AUTOSAR XML (schema 00044)
package /E40_Platform_System_SystemPackage/Components
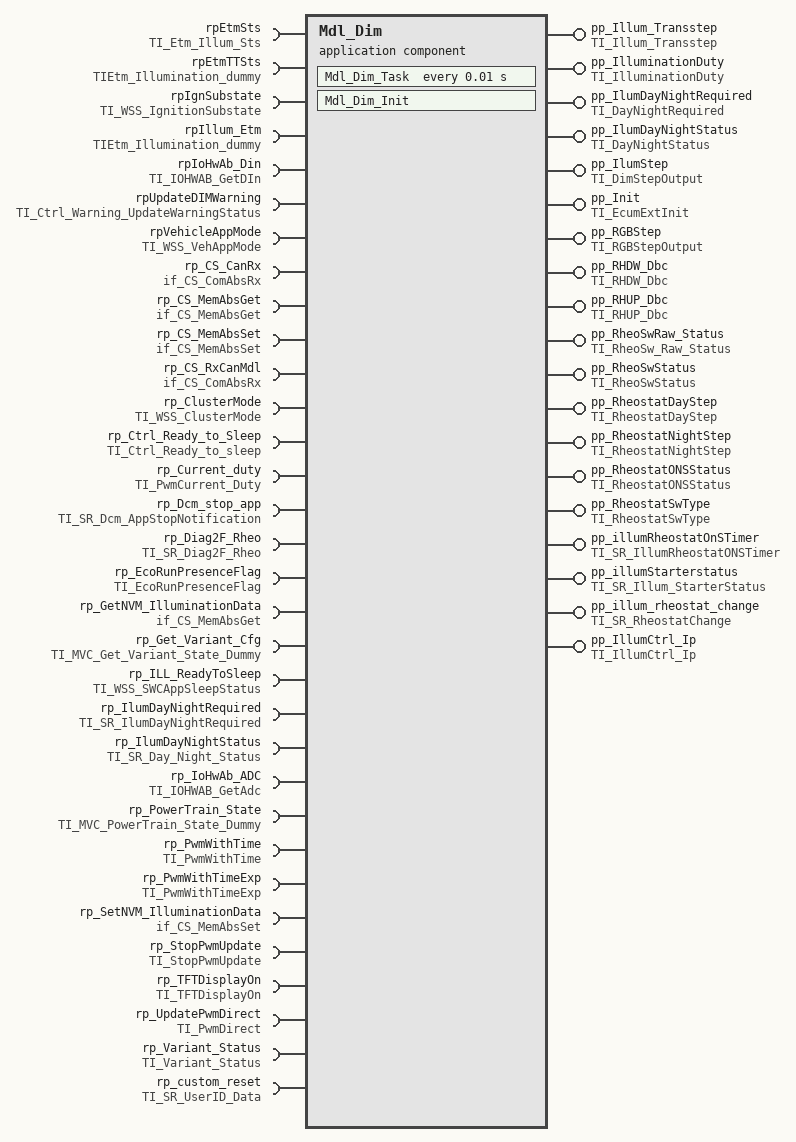
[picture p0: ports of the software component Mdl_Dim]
  application sw component type Mdl_Dim
    18 x provide port:
      pp_Illum_Transstep: nonqueued-sender-com-spec{data-element=Trans_Stepvlaue, init-value=constant-reference=Mdl_DimTrans_StepvlaueValue0}, provided-interface=TI_Illum_Transstep
      pp_IlluminationDuty: nonqueued-sender-com-spec{data-element=DutyValue, init-value=constant-reference=Mdl_DimDutyValueValue0}, provided-interface=TI_IlluminationDuty
      pp_IlumDayNightRequired: nonqueued-sender-com-spec{data-element=ilumDNRequired, init-value=constant-reference=Mdl_DimilumDNRequiredValue0}, provided-interface=TI_DayNightRequired
      pp_IlumDayNightStatus: nonqueued-sender-com-spec{data-element=illumDNStatus, init-value=constant-reference=Mdl_DimillumDNStatusValue0}, provided-interface=TI_DayNightStatus
      pp_IlumStep: nonqueued-sender-com-spec{data-element=IllumStepValue, init-value=constant-reference=Mdl_DimIllumStepValueValue0}, provided-interface=TI_DimStepOutput
      pp_Init: server-com-spec{operation=Init, queue-length=1}, provided-interface=TI_EcumExtInit
      pp_RGBStep: nonqueued-sender-com-spec{data-element=RGBStepValue, init-value=constant-reference=Mdl_DimRGBStepValueValue0}, provided-interface=TI_RGBStepOutput
      pp_RHDW_Dbc: nonqueued-sender-com-spec{data-element=RHDW_Dbc, init-value=constant-reference=Mdl_DimRHDW_DbcValue0}, provided-interface=TI_RHDW_Dbc
      pp_RHUP_Dbc: nonqueued-sender-com-spec{data-element=RHUP_Dbc, init-value=constant-reference=Mdl_DimRHUP_DbcValue0}, provided-interface=TI_RHUP_Dbc
      pp_RheoSwRaw_Status: nonqueued-sender-com-spec{data-element=RawdataStatus, init-value=constant-reference=Mdl_DimRawdataStatusValue0}, provided-interface=TI_RheoSw_Raw_Status
      pp_RheoSwStatus: nonqueued-sender-com-spec{data-element=SwitchStatus, init-value=constant-reference=Mdl_DimSwitchStatusValue0}, provided-interface=TI_RheoSwStatus
      pp_RheostatDayStep: nonqueued-sender-com-spec{data-element=RheostatDayStep, init-value=constant-reference=Mdl_DimRheostatDayStepValue0}, provided-interface=TI_RheostatDayStep
      pp_RheostatNightStep: nonqueued-sender-com-spec{data-element=RheostatNightStep, init-value=constant-reference=Mdl_DimRheostatNightStepValue0}, provided-interface=TI_RheostatNightStep
      pp_RheostatONSStatus: nonqueued-sender-com-spec{data-element=RheostatONSStatus, init-value=constant-reference=Mdl_DimRheostatONSStatusValue0}, provided-interface=TI_RheostatONSStatus
      pp_RheostatSwType: nonqueued-sender-com-spec{data-element=RheostatSwType, init-value=constant-reference=Mdl_DimRheostatSwTypeValue0}, provided-interface=TI_RheostatSwType
      pp_illumRheostatOnSTimer: nonqueued-sender-com-spec{data-element=Rheostat_OnSTime, init-value=constant-reference=Mdl_DimRheostat_OnSTimeValue0}, provided-interface=TI_SR_IllumRheostatONSTimer
      pp_illumStarterstatus: nonqueued-sender-com-spec{data-element=StarterStatus_Out, init-value=constant-reference=Mdl_DimStarterStatus_OutValue0}, provided-interface=TI_SR_Illum_StarterStatus
      pp_illum_rheostat_change: nonqueued-sender-com-spec{data-element=RheoUpdateVal, init-value=constant-reference=Mdl_DimRheoUpdateValValue0}, provided-interface=TI_SR_RheostatChange
    32 x require port:
      rpEtmSts: nonqueued-receiver-com-spec{data-element=Illum_Status, init-value=constant-reference=Mdl_DimIllum_StatusValue0}, required-interface=TI_Etm_Illum_Sts
      rpEtmTTSts: nonqueued-receiver-com-spec{data-element=IllumStatus, init-value=constant-reference=Mdl_DimIllumStatusValue0}, required-interface=TIEtm_Illumination_dummy
      rpIgnSubstate: nonqueued-receiver-com-spec{data-element=IgnitionSubstate, init-value=constant-reference=Mdl_DimIgnitionSubstateValue0}, required-interface=TI_WSS_IgnitionSubstate
      rpIllum_Etm: nonqueued-receiver-com-spec{data-element=IllumStatus, init-value=constant-reference=Mdl_DimIllumStatusValue0}, required-interface=TIEtm_Illumination_dummy
      rpIoHwAb_Din: required-com-specs=[GetAsyncRawInput, GetInputGroup, GetProcessedInput, GetSyncRawInput], required-interface=TI_IOHWAB_GetDIn
      rpUpdateDIMWarning: client-com-spec=UpdateWarningStatus, required-interface=TI_Ctrl_Warning_UpdateWarningStatus
      rpVehicleAppMode: nonqueued-receiver-com-spec{data-element=WSSCurrentVehicleState, init-value=constant-reference=Mdl_DimWSSCurrentVehicleStateValue0}, required-interface=TI_WSS_VehAppMode
      rp_CS_CanRx: required-interface=if_CS_ComAbsRx
        required-com-specs:
          RxCan_GetSignalValue
          RxCan_GetSignalValueU8Arr
          RxCan_SetSignalInitValue
          RxCan_SetSignalInitValueU8Arr
          RxCan_SignalClearJustRcvdStatus
          RxCan_SignalGetJustRcvdStatus
          RxCan_SignalInvalidProcessingControl
          RxCan_SignalMissingProcessingControl
          RxCan_SignalNRProcessingControl
      rp_CS_MemAbsGet: required-interface=if_CS_MemAbsGet
        required-com-specs:
          Get_BsConst_Audio_Element
          Get_BsConst_Communication_Element
          Get_BsConst_EngOffTimer_Element
          Get_BsConst_FuelGauge_Element
          Get_BsConst_OilGauge_Element
          Get_BsConst_PowerGauge_Element
          Get_BsConst_Power_Element
          Get_BsConst_RealTimeClock_Element
          Get_BsConst_ServiceReminder_Element
          Get_BsConst_SpeedoGauge_Element
          Get_BsConst_TachoGauge_Element
          Get_BsConst_TempGauge_Element
          Get_BsConst_TripComputer_Element
          Get_BsConst_Warning_Element
          Get_BsCys_Certicificate_Element
          Get_BsDiag_Dtc_Element
          Get_BsDiag_ErrorRecord_Element
          Get_BsReten_Audio_Element
          Get_BsReten_Communication_Element
          Get_BsReten_Display_Element
          Get_BsReten_Gauges_Element
          Get_BsReten_Illumination_Element
          Get_BsReten_Odometer_Element
          Get_BsReten_Personalization_Element
          Get_BsReten_Power_Element
          Get_BsReten_RealTimeClock_Element
          Get_BsReten_Tripcomputer_Element
          Get_BsReten_Warning_Element
          Get_BsRt_CusDlt_Element
          Get_BsRt_FuelGauge_Element
          Get_BsRt_Illumination_Element
          Get_BsRt_Odometer_Element
          Get_BsRt_OilGauge_Element
          Get_BsRt_Personalization_Element
          Get_BsRt_PowerGauge_Element
          Get_BsRt_RealTimeClock_Element
          Get_BsRt_SpeedoGauge_Element
          Get_BsRt_TachoGauge_Element
          Get_BsRt_TempGauge_Element
          Get_BsRt_TripComputer_Element
          Get_BsRt_Warning_Element
          Get_BsShare_EcuPartNumber_Element
          Get_BsShare_SwUpdFotaFinPrint_Element
          Get_BsShare_SwUpdFotaMode_Element
          Get_BsShare_SwUpdFotaStatus_Element
          Get_BsShare_SwUpdFotadecrypt_Element
          Get_BsShare_SwUpdReflash_Element
          Get_BsShare_VehicleConfig_Element
          Get_BsShare_VisMeet_Element
          Get_RefCys_Certicificate1_Element
          Get_RefCys_Certicificate_Element
          Get_BsShare_VisMeet_EOLEntry_Element
          Get_BsShare_AssemblyManufacturingDate
          Get_BsShare_AssemblyPlantNumber
          Get_BsShare_HWModification
          Get_BsShare_PCBSerialNumber
          Get_BsShare_ProductSerialNumber
          Get_BsShare_SMTManufacturingDate
          Get_BsShare_SMTPlantNumber
          Get_BsShare_VisteonPCBPartNumber
          Get_BsShare_VisteonPartNumber
          Get_BsConst_Temperature_Sensor_Conv_SafeCopy2
          Get_BsConst_Temperature_Sensor_Conv_SafeCopy1
          Get_BsConst_Temperature_Sensor_Conv
          Get_BsConst_Temp_Threshold_Hysteresis_Derating_SafeCopy2
          Get_BsConst_Temp_Threshold_Hysteresis_Derating_SafeCopy1
          Get_BsConst_Temp_Threshold_Hysteresis_Derating
          Get_BsConst_PWM_boost_bypass_duty_SafeCopy2
          Get_BsConst_PWM_boost_bypass_duty_SafeCopy1
          Get_BsConst_PWM_boost_bypass_duty
          Get_BsConst_PCB_Temperature_Sensor_Conv_SafeCopy2
          Get_BsConst_PCB_Temperature_Sensor_Conv_SafeCopy1
          Get_BsConst_PCB_Temperature_Sensor_Conv
          Get_BsConst_Lookup_Curve_HotSpot_Coef_Y_SafeCopy2
          Get_BsConst_Lookup_Curve_HotSpot_Coef_Y_SafeCopy1
          Get_BsConst_Lookup_Curve_HotSpot_Coef_Y
          Get_BsConst_Lookup_Curve_HotSpot_Coef_X_SafeCopy2
          Get_BsConst_Lookup_Curve_HotSpot_Coef_X_SafeCopy1
          Get_BsConst_Lookup_Curve_HotSpot_Coef_X
          Get_BsConst_Display_Illum_Max_Level_SafeCopy2
          Get_BsConst_Display_Illum_Max_Level_SafeCopy1
          Get_BsConst_Display_Illum_Max_Level
          Get_BsConst_Derating_Backlight_Disable_SafeCopy2
          Get_BsConst_Derating_Backlight_Disable_SafeCopy1
          Get_BsConst_Derating_Backlight_Disable
          Get_BsConst_Compensation_Line_Slope_m_SafeCopy2
          Get_BsConst_Compensation_Line_Slope_m_SafeCopy1
          Get_BsConst_Compensation_Line_Slope_m
          Get_BsConst_Compensation_Line_Shift_b_SafeCopy2
          Get_BsConst_Compensation_Line_Shift_b_SafeCopy1
          Get_BsConst_Compensation_Line_Shift_b
          Get_BsConst_BsConst_Illumination_ReservedByte_SafeCopy2
          Get_BsConst_BsConst_Illumination_ReservedByte_SafeCopy1
          Get_BsConst_BsConst_Illumination_ReservedByte
      rp_CS_MemAbsSet: required-interface=if_CS_MemAbsSet
        required-com-specs:
          Set_BsConst_Audio_Element
          Set_BsConst_Communication_Element
          Set_BsConst_EngOffTimer_Element
          Set_BsConst_FuelGauge_Element
          Set_BsConst_OilGauge_Element
          Set_BsConst_PowerGauge_Element
          Set_BsConst_Power_Element
          Set_BsConst_RealTimeClock_Element
          Set_BsConst_ServiceReminder_Element
          Set_BsConst_SpeedoGauge_Element
          Set_BsConst_TachoGauge_Element
          Set_BsConst_TempGauge_Element
          Set_BsConst_TripComputer_Element
          Set_BsConst_Warning_Element
          Set_BsCys_Certicificate_Element
          Set_BsDiag_Dtc_Element
          Set_BsDiag_ErrorRecord_Element
          Set_BsReten_Audio_Element
          Set_BsReten_Communication_Element
          Set_BsReten_Display_Element
          Set_BsReten_Gauges_Element
          Set_BsReten_Illumination_Element
          Set_BsReten_Odometer_Element
          Set_BsReten_Personalization_Element
          Set_BsReten_Power_Element
          Set_BsReten_RealTimeClock_Element
          Set_BsReten_Tripcomputer_Element
          Set_BsReten_Warning_Element
          Set_BsRt_CusDlt_Element
          Set_BsRt_FuelGauge_Element
          Set_BsRt_Illumination_Element
          Set_BsRt_Odometer_Element
          Set_BsRt_OilGauge_Element
          Set_BsRt_Personalization_Element
          Set_BsRt_PowerGauge_Element
          Set_BsRt_RealTimeClock_Element
          Set_BsRt_SpeedoGauge_Element
          Set_BsRt_TachoGauge_Element
          Set_BsRt_TempGauge_Element
          Set_BsRt_TripComputer_Element
          Set_BsRt_Warning_Element
          Set_BsShare_EcuPartNumber_Element
          Set_BsShare_SwUpdFotaFinPrint_Element
          Set_BsShare_SwUpdFotaMode_Element
          Set_BsShare_SwUpdFotaStatus_Element
          Set_BsShare_SwUpdFotadecrypt_Element
          Set_BsShare_SwUpdReflash_Element
          Set_BsShare_VehicleConfig_Element
          Set_BsShare_VisMeet_Element
          Set_RefCys_Certicificate1_Element
          Set_RefCys_Certicificate_Element
          Set_BsShare_VisMeet_EOLEntry_Element
          Set_BsShare_AssemblyManufacturingDate
          Set_BsShare_AssemblyPlantNumber
          Set_BsShare_HWModification
          Set_BsShare_PCBSerialNumber
          Set_BsShare_ProductSerialNumber
          Set_BsShare_SMTManufacturingDate
          Set_BsShare_SMTPlantNumber
          Set_BsShare_VisteonPCBPartNumber
          Set_BsShare_VisteonPartNumber
          Set_BsConst_Temperature_Sensor_Conv_SafeCopy2
          Set_BsConst_Temperature_Sensor_Conv_SafeCopy1
          Set_BsConst_Temperature_Sensor_Conv
          Set_BsConst_Temp_Threshold_Hysteresis_Derating_SafeCopy2
          Set_BsConst_Temp_Threshold_Hysteresis_Derating_SafeCopy1
          Set_BsConst_Temp_Threshold_Hysteresis_Derating
          Set_BsConst_PWM_boost_bypass_duty_SafeCopy2
          Set_BsConst_PWM_boost_bypass_duty_SafeCopy1
          Set_BsConst_PWM_boost_bypass_duty
          Set_BsConst_PCB_Temperature_Sensor_Conv_SafeCopy2
          Set_BsConst_PCB_Temperature_Sensor_Conv_SafeCopy1
          Set_BsConst_PCB_Temperature_Sensor_Conv
          Set_BsConst_Lookup_Curve_HotSpot_Coef_Y_SafeCopy2
          Set_BsConst_Lookup_Curve_HotSpot_Coef_Y_SafeCopy1
          Set_BsConst_Lookup_Curve_HotSpot_Coef_Y
          Set_BsConst_Lookup_Curve_HotSpot_Coef_X_SafeCopy2
          Set_BsConst_Lookup_Curve_HotSpot_Coef_X_SafeCopy1
          Set_BsConst_Lookup_Curve_HotSpot_Coef_X
          Set_BsConst_Display_Illum_Max_Level_SafeCopy2
          Set_BsConst_Display_Illum_Max_Level_SafeCopy1
          Set_BsConst_Display_Illum_Max_Level
          Set_BsConst_Derating_Backlight_Disable_SafeCopy2
          Set_BsConst_Derating_Backlight_Disable_SafeCopy1
          Set_BsConst_Derating_Backlight_Disable
          Set_BsConst_Compensation_Line_Slope_m_SafeCopy2
          Set_BsConst_Compensation_Line_Slope_m_SafeCopy1
          Set_BsConst_Compensation_Line_Slope_m
          Set_BsConst_Compensation_Line_Shift_b_SafeCopy2
          Set_BsConst_Compensation_Line_Shift_b_SafeCopy1
          Set_BsConst_Compensation_Line_Shift_b
          Set_BsConst_BsConst_Illumination_ReservedByte_SafeCopy2
          Set_BsConst_BsConst_Illumination_ReservedByte_SafeCopy1
          Set_BsConst_BsConst_Illumination_ReservedByte
      rp_CS_RxCanMdl: required-interface=if_CS_ComAbsRx
        required-com-specs:
          RxCan_GetSignalValue
          RxCan_GetSignalValueU8Arr
          RxCan_SetSignalInitValue
          RxCan_SetSignalInitValueU8Arr
          RxCan_SignalClearJustRcvdStatus
          RxCan_SignalGetJustRcvdStatus
          RxCan_SignalInvalidProcessingControl
          RxCan_SignalMissingProcessingControl
          RxCan_SignalNRProcessingControl
      rp_ClusterMode: nonqueued-receiver-com-spec{data-element=WSSCurrentClusterMode, init-value=constant-reference=Mdl_DimWSSCurrentClusterModeValue0}, required-interface=TI_WSS_ClusterMode
      rp_Ctrl_Ready_to_Sleep: nonqueued-receiver-com-spec{data-element=Ready_to_Sleep, init-value=constant-reference=Mdl_DimReady_to_SleepValue0}, required-interface=TI_Ctrl_Ready_to_sleep
      rp_Current_duty: client-com-spec=GetPwmCurrentDuty, required-interface=TI_PwmCurrent_Duty
      rp_Dcm_stop_app: nonqueued-receiver-com-spec{data-element=AppId, init-value=constant-reference=Mdl_DimAppIdValue0}, required-interface=TI_SR_Dcm_AppStopNotification
      rp_Diag2F_Rheo: nonqueued-receiver-com-spec{data-element=Diag_RheoStat, init-value=constant-reference=Mdl_DimDiag_RheoStatValue0}, required-interface=TI_SR_Diag2F_Rheo
      rp_EcoRunPresenceFlag: nonqueued-receiver-com-spec{data-element=EcoRunPresenceFlag, init-value=constant-reference=Mdl_DimEcoRunPresenceFlagValue0}, required-interface=TI_EcoRunPresenceFlag
      rp_GetNVM_IlluminationData: required-interface=if_CS_MemAbsGet
        required-com-specs:
          Get_BsConst_Audio_Element
          Get_BsConst_Communication_Element
          Get_BsConst_EngOffTimer_Element
          Get_BsConst_FuelGauge_Element
          Get_BsConst_OilGauge_Element
          Get_BsConst_PowerGauge_Element
          Get_BsConst_Power_Element
          Get_BsConst_RealTimeClock_Element
          Get_BsConst_ServiceReminder_Element
          Get_BsConst_SpeedoGauge_Element
          Get_BsConst_TachoGauge_Element
          Get_BsConst_TempGauge_Element
          Get_BsConst_TripComputer_Element
          Get_BsConst_Warning_Element
          Get_BsCys_Certicificate_Element
          Get_BsDiag_Dtc_Element
          Get_BsDiag_ErrorRecord_Element
          Get_BsReten_Audio_Element
          Get_BsReten_Communication_Element
          Get_BsReten_Display_Element
          Get_BsReten_Gauges_Element
          Get_BsReten_Illumination_Element
          Get_BsReten_Odometer_Element
          Get_BsReten_Personalization_Element
          Get_BsReten_Power_Element
          Get_BsReten_RealTimeClock_Element
          Get_BsReten_Tripcomputer_Element
          Get_BsReten_Warning_Element
          Get_BsRt_CusDlt_Element
          Get_BsRt_FuelGauge_Element
          Get_BsRt_Illumination_Element
          Get_BsRt_Odometer_Element
          Get_BsRt_OilGauge_Element
          Get_BsRt_Personalization_Element
          Get_BsRt_PowerGauge_Element
          Get_BsRt_RealTimeClock_Element
          Get_BsRt_SpeedoGauge_Element
          Get_BsRt_TachoGauge_Element
          Get_BsRt_TempGauge_Element
          Get_BsRt_TripComputer_Element
          Get_BsRt_Warning_Element
          Get_BsShare_EcuPartNumber_Element
          Get_BsShare_SwUpdFotaFinPrint_Element
          Get_BsShare_SwUpdFotaMode_Element
          Get_BsShare_SwUpdFotaStatus_Element
          Get_BsShare_SwUpdFotadecrypt_Element
          Get_BsShare_SwUpdReflash_Element
          Get_BsShare_VehicleConfig_Element
          Get_BsShare_VisMeet_Element
          Get_RefCys_Certicificate1_Element
          Get_RefCys_Certicificate_Element
          Get_BsShare_VisMeet_EOLEntry_Element
          Get_BsShare_AssemblyManufacturingDate
          Get_BsShare_AssemblyPlantNumber
          Get_BsShare_HWModification
          Get_BsShare_PCBSerialNumber
          Get_BsShare_ProductSerialNumber
          Get_BsShare_SMTManufacturingDate
          Get_BsShare_SMTPlantNumber
          Get_BsShare_VisteonPCBPartNumber
          Get_BsShare_VisteonPartNumber
          Get_BsConst_Temperature_Sensor_Conv_SafeCopy2
          Get_BsConst_Temperature_Sensor_Conv_SafeCopy1
          Get_BsConst_Temperature_Sensor_Conv
          Get_BsConst_Temp_Threshold_Hysteresis_Derating_SafeCopy2
          Get_BsConst_Temp_Threshold_Hysteresis_Derating_SafeCopy1
          Get_BsConst_Temp_Threshold_Hysteresis_Derating
          Get_BsConst_PWM_boost_bypass_duty_SafeCopy2
          Get_BsConst_PWM_boost_bypass_duty_SafeCopy1
          Get_BsConst_PWM_boost_bypass_duty
          Get_BsConst_PCB_Temperature_Sensor_Conv_SafeCopy2
          Get_BsConst_PCB_Temperature_Sensor_Conv_SafeCopy1
          Get_BsConst_PCB_Temperature_Sensor_Conv
          Get_BsConst_Lookup_Curve_HotSpot_Coef_Y_SafeCopy2
          Get_BsConst_Lookup_Curve_HotSpot_Coef_Y_SafeCopy1
          Get_BsConst_Lookup_Curve_HotSpot_Coef_Y
          Get_BsConst_Lookup_Curve_HotSpot_Coef_X_SafeCopy2
          Get_BsConst_Lookup_Curve_HotSpot_Coef_X_SafeCopy1
          Get_BsConst_Lookup_Curve_HotSpot_Coef_X
          Get_BsConst_Display_Illum_Max_Level_SafeCopy2
          Get_BsConst_Display_Illum_Max_Level_SafeCopy1
          Get_BsConst_Display_Illum_Max_Level
          Get_BsConst_Derating_Backlight_Disable_SafeCopy2
          Get_BsConst_Derating_Backlight_Disable_SafeCopy1
          Get_BsConst_Derating_Backlight_Disable
          Get_BsConst_Compensation_Line_Slope_m_SafeCopy2
          Get_BsConst_Compensation_Line_Slope_m_SafeCopy1
          Get_BsConst_Compensation_Line_Slope_m
          Get_BsConst_Compensation_Line_Shift_b_SafeCopy2
          Get_BsConst_Compensation_Line_Shift_b_SafeCopy1
          Get_BsConst_Compensation_Line_Shift_b
          Get_BsConst_BsConst_Illumination_ReservedByte_SafeCopy2
          Get_BsConst_BsConst_Illumination_ReservedByte_SafeCopy1
          Get_BsConst_BsConst_Illumination_ReservedByte
      rp_Get_Variant_Cfg: client-com-spec=Get_Variant_Config_State, required-interface=TI_MVC_Get_Variant_State_Dummy
      rp_ILL_ReadyToSleep: client-com-spec=SWCSleepStatus, required-interface=TI_WSS_SWCAppSleepStatus
      rp_IlumDayNightRequired: nonqueued-receiver-com-spec{data-element=IlumDayNightRequired, init-value=constant-reference=Mdl_DimIlumDayNightRequiredValue0}, required-interface=TI_SR_IlumDayNightRequired
      rp_IlumDayNightStatus: nonqueued-receiver-com-spec{data-element=Day_Night_Status, init-value=constant-reference=Mdl_DimDay_Night_StatusValue0}, required-interface=TI_SR_Day_Night_Status
      rp_IoHwAb_ADC: required-com-specs=[GetAsyncRawAdc, GetProcessedAdc, GetSyncRawAdc], required-interface=TI_IOHWAB_GetAdc
      rp_PowerTrain_State: nonqueued-receiver-com-spec{data-element=PowerTrain_Flag, init-value=constant-reference=Mdl_DimPowerTrain_FlagValue0}, required-interface=TI_MVC_PowerTrain_State_Dummy
      rp_PwmWithTime: client-com-spec=GetPwmWithTime, required-interface=TI_PwmWithTime
      rp_PwmWithTimeExp: client-com-spec=GetPwmWithTimeExp, required-interface=TI_PwmWithTimeExp
      rp_SetNVM_IlluminationData: required-interface=if_CS_MemAbsSet
        required-com-specs:
          Set_BsConst_Audio_Element
          Set_BsConst_Communication_Element
          Set_BsConst_EngOffTimer_Element
          Set_BsConst_FuelGauge_Element
          Set_BsConst_OilGauge_Element
          Set_BsConst_PowerGauge_Element
          Set_BsConst_Power_Element
          Set_BsConst_RealTimeClock_Element
          Set_BsConst_ServiceReminder_Element
          Set_BsConst_SpeedoGauge_Element
          Set_BsConst_TachoGauge_Element
          Set_BsConst_TempGauge_Element
          Set_BsConst_TripComputer_Element
          Set_BsConst_Warning_Element
          Set_BsCys_Certicificate_Element
          Set_BsDiag_Dtc_Element
          Set_BsDiag_ErrorRecord_Element
          Set_BsReten_Audio_Element
          Set_BsReten_Communication_Element
          Set_BsReten_Display_Element
          Set_BsReten_Gauges_Element
          Set_BsReten_Illumination_Element
          Set_BsReten_Odometer_Element
          Set_BsReten_Personalization_Element
          Set_BsReten_Power_Element
          Set_BsReten_RealTimeClock_Element
          Set_BsReten_Tripcomputer_Element
          Set_BsReten_Warning_Element
          Set_BsRt_CusDlt_Element
          Set_BsRt_FuelGauge_Element
          Set_BsRt_Illumination_Element
          Set_BsRt_Odometer_Element
          Set_BsRt_OilGauge_Element
          Set_BsRt_Personalization_Element
          Set_BsRt_PowerGauge_Element
          Set_BsRt_RealTimeClock_Element
          Set_BsRt_SpeedoGauge_Element
          Set_BsRt_TachoGauge_Element
          Set_BsRt_TempGauge_Element
          Set_BsRt_TripComputer_Element
          Set_BsRt_Warning_Element
          Set_BsShare_EcuPartNumber_Element
          Set_BsShare_SwUpdFotaFinPrint_Element
          Set_BsShare_SwUpdFotaMode_Element
          Set_BsShare_SwUpdFotaStatus_Element
          Set_BsShare_SwUpdFotadecrypt_Element
          Set_BsShare_SwUpdReflash_Element
          Set_BsShare_VehicleConfig_Element
          Set_BsShare_VisMeet_Element
          Set_RefCys_Certicificate1_Element
          Set_RefCys_Certicificate_Element
          Set_BsShare_VisMeet_EOLEntry_Element
          Set_BsShare_AssemblyManufacturingDate
          Set_BsShare_AssemblyPlantNumber
          Set_BsShare_HWModification
          Set_BsShare_PCBSerialNumber
          Set_BsShare_ProductSerialNumber
          Set_BsShare_SMTManufacturingDate
          Set_BsShare_SMTPlantNumber
          Set_BsShare_VisteonPCBPartNumber
          Set_BsShare_VisteonPartNumber
          Set_BsConst_Temperature_Sensor_Conv_SafeCopy2
          Set_BsConst_Temperature_Sensor_Conv_SafeCopy1
          Set_BsConst_Temperature_Sensor_Conv
          Set_BsConst_Temp_Threshold_Hysteresis_Derating_SafeCopy2
          Set_BsConst_Temp_Threshold_Hysteresis_Derating_SafeCopy1
          Set_BsConst_Temp_Threshold_Hysteresis_Derating
          Set_BsConst_PWM_boost_bypass_duty_SafeCopy2
          Set_BsConst_PWM_boost_bypass_duty_SafeCopy1
          Set_BsConst_PWM_boost_bypass_duty
          Set_BsConst_PCB_Temperature_Sensor_Conv_SafeCopy2
          Set_BsConst_PCB_Temperature_Sensor_Conv_SafeCopy1
          Set_BsConst_PCB_Temperature_Sensor_Conv
          Set_BsConst_Lookup_Curve_HotSpot_Coef_Y_SafeCopy2
          Set_BsConst_Lookup_Curve_HotSpot_Coef_Y_SafeCopy1
          Set_BsConst_Lookup_Curve_HotSpot_Coef_Y
          Set_BsConst_Lookup_Curve_HotSpot_Coef_X_SafeCopy2
          Set_BsConst_Lookup_Curve_HotSpot_Coef_X_SafeCopy1
          Set_BsConst_Lookup_Curve_HotSpot_Coef_X
          Set_BsConst_Display_Illum_Max_Level_SafeCopy2
          Set_BsConst_Display_Illum_Max_Level_SafeCopy1
          Set_BsConst_Display_Illum_Max_Level
          Set_BsConst_Derating_Backlight_Disable_SafeCopy2
          Set_BsConst_Derating_Backlight_Disable_SafeCopy1
          Set_BsConst_Derating_Backlight_Disable
          Set_BsConst_Compensation_Line_Slope_m_SafeCopy2
          Set_BsConst_Compensation_Line_Slope_m_SafeCopy1
          Set_BsConst_Compensation_Line_Slope_m
          Set_BsConst_Compensation_Line_Shift_b_SafeCopy2
          Set_BsConst_Compensation_Line_Shift_b_SafeCopy1
          Set_BsConst_Compensation_Line_Shift_b
          Set_BsConst_BsConst_Illumination_ReservedByte_SafeCopy2
          Set_BsConst_BsConst_Illumination_ReservedByte_SafeCopy1
          Set_BsConst_BsConst_Illumination_ReservedByte
      rp_StopPwmUpdate: nonqueued-receiver-com-spec{data-element=channel_id, init-value=constant-reference=Mdl_Dimchannel_idValue0}, required-interface=TI_StopPwmUpdate
      rp_TFTDisplayOn: nonqueued-receiver-com-spec{data-element=TFTDisplayOn, init-value=constant-reference=Mdl_DimTFTDisplayOnValue0}, required-interface=TI_TFTDisplayOn
      rp_UpdatePwmDirect: client-com-spec=GetPwmDirect, required-interface=TI_PwmDirect
      rp_Variant_Status: client-com-spec=GetVariant_Status, required-interface=TI_Variant_Status
      rp_custom_reset: required-interface=TI_SR_UserID_Data
        required-com-specs:
          data-element=CurrentUserID, init-value=constant-reference=Mdl_DimCurrentUserIDValue0
          data-element=CustomizeReset, init-value=constant-reference=Mdl_DimCustomizeResetValue0
          data-element=SettingResetResult, init-value=constant-reference=Mdl_DimSettingResetResultValue0
    provide port pp_IllumCtrl_Ip: nonqueued-sender-com-spec{data-element=IllumCtrl_Ip_Data, init-value=constant-reference=Mdl_DimIllumCtrl_Ip_DataValue0}, provided-interface=TI_IllumCtrl_Ip
    behavior IB_Mdl_Dim
      operation invoked event OIE_pp_Init_Mdl_Dim_InitTrigByInit: start-on-event=Mdl_Dim_Init, operation=pp_Init.Init
      timing event TEMdl_Dim_Task: start-on-event=Mdl_Dim_Task, period=0.01
      port-api-options:
        enable-take-address=false, indirect-api=false, port=pp_Illum_Transstep
        enable-take-address=false, indirect-api=false, port=pp_IlluminationDuty
        enable-take-address=false, indirect-api=false, port=pp_IlumDayNightRequired
        enable-take-address=false, indirect-api=false, port=pp_IlumDayNightStatus
        enable-take-address=false, indirect-api=false, port=pp_IlumStep
        enable-take-address=false, indirect-api=false, port=pp_Init
        enable-take-address=false, indirect-api=false, port=pp_RGBStep
        enable-take-address=false, indirect-api=false, port=pp_RHDW_Dbc
        enable-take-address=false, indirect-api=false, port=pp_RHUP_Dbc
        enable-take-address=false, indirect-api=false, port=pp_RheoSwRaw_Status
        enable-take-address=false, indirect-api=false, port=pp_RheoSwStatus
        enable-take-address=false, indirect-api=false, port=pp_RheostatDayStep
        enable-take-address=false, indirect-api=false, port=pp_RheostatNightStep
        enable-take-address=false, indirect-api=false, port=pp_RheostatONSStatus
        enable-take-address=false, indirect-api=false, port=pp_RheostatSwType
        enable-take-address=false, indirect-api=false, port=pp_illumRheostatOnSTimer
        enable-take-address=false, indirect-api=false, port=pp_illumStarterstatus
        enable-take-address=false, indirect-api=false, port=pp_illum_rheostat_change
        enable-take-address=false, indirect-api=false, port=rpEtmSts
        enable-take-address=false, indirect-api=false, port=rpEtmTTSts
        enable-take-address=false, indirect-api=false, port=rpIgnSubstate
        enable-take-address=false, indirect-api=false, port=rpIllum_Etm
        enable-take-address=false, indirect-api=false, port=rpIoHwAb_Din
        enable-take-address=false, indirect-api=false, port=rpUpdateDIMWarning
        enable-take-address=false, indirect-api=false, port=rpVehicleAppMode
        enable-take-address=false, indirect-api=false, port=rp_CS_CanRx
        enable-take-address=false, indirect-api=false, port=rp_CS_MemAbsGet
        enable-take-address=false, indirect-api=false, port=rp_CS_MemAbsSet
        enable-take-address=false, indirect-api=false, port=rp_CS_RxCanMdl
        enable-take-address=false, indirect-api=false, port=rp_ClusterMode
        enable-take-address=false, indirect-api=false, port=rp_Ctrl_Ready_to_Sleep
        enable-take-address=false, indirect-api=false, port=rp_Current_duty
        enable-take-address=false, indirect-api=false, port=rp_Dcm_stop_app
        enable-take-address=false, indirect-api=false, port=rp_Diag2F_Rheo
        enable-take-address=false, indirect-api=false, port=rp_EcoRunPresenceFlag
        enable-take-address=false, indirect-api=false, port=rp_GetNVM_IlluminationData
        enable-take-address=false, indirect-api=false, port=rp_Get_Variant_Cfg
        enable-take-address=false, indirect-api=false, port=rp_ILL_ReadyToSleep
        enable-take-address=false, indirect-api=false, port=rp_IlumDayNightRequired
        enable-take-address=false, indirect-api=false, port=rp_IlumDayNightStatus
        enable-take-address=false, indirect-api=false, port=rp_IoHwAb_ADC
        enable-take-address=false, indirect-api=false, port=rp_PowerTrain_State
        enable-take-address=false, indirect-api=false, port=rp_PwmWithTime
        enable-take-address=false, indirect-api=false, port=rp_PwmWithTimeExp
        enable-take-address=false, indirect-api=false, port=rp_SetNVM_IlluminationData
        enable-take-address=false, indirect-api=false, port=rp_StopPwmUpdate
        enable-take-address=false, indirect-api=false, port=rp_TFTDisplayOn
        enable-take-address=false, indirect-api=false, port=rp_UpdatePwmDirect
        enable-take-address=false, indirect-api=false, port=rp_Variant_Status
        enable-take-address=false, indirect-api=false, port=rp_custom_reset
        enable-take-address=false, indirect-api=false, port=pp_IllumCtrl_Ip
      runnable Mdl_Dim_Init: can-be-invoked-concurrently=true
      runnable Mdl_Dim_Task: can-be-invoked-concurrently=true
        data-receive-point-by-arguments:
          18 x access:
            DRA_rpEtmSts_Illum_Status: accessed-variable=rpEtmSts.Illum_Status
            DRA_rpEtmTTSts_IllumStatus: accessed-variable=rpEtmTTSts.IllumStatus
            DRA_rpIgnSubstate_IgnitionSubstate: accessed-variable=rpIgnSubstate.IgnitionSubstate
            DRA_rpIllum_Etm_IllumStatus: accessed-variable=rpIllum_Etm.IllumStatus
            DRA_rpVehicleAppMode_WSSCurrentVehicleState: accessed-variable=rpVehicleAppMode.WSSCurrentVehicleState
            DRA_rp_ClusterMode_WSSCurrentClusterMode: accessed-variable=rp_ClusterMode.WSSCurrentClusterMode
            DRA_rp_Ctrl_Ready_to_Sleep_Ready_to_Sleep: accessed-variable=rp_Ctrl_Ready_to_Sleep.Ready_to_Sleep
            DRA_rp_Dcm_stop_app_AppId: accessed-variable=rp_Dcm_stop_app.AppId
            DRA_rp_Diag2F_Rheo_Diag_RheoStat: accessed-variable=rp_Diag2F_Rheo.Diag_RheoStat
            DRA_rp_EcoRunPresenceFlag_EcoRunPresenceFlag: accessed-variable=rp_EcoRunPresenceFlag.EcoRunPresenceFlag
            DRA_rp_IlumDayNightRequired_IlumDayNightRequired: accessed-variable=rp_IlumDayNightRequired.IlumDayNightRequired
            DRA_rp_IlumDayNightStatus_Day_Night_Status: accessed-variable=rp_IlumDayNightStatus.Day_Night_Status
            DRA_rp_PowerTrain_State_PowerTrain_Flag: accessed-variable=rp_PowerTrain_State.PowerTrain_Flag
            DRA_rp_StopPwmUpdate_channel_id: accessed-variable=rp_StopPwmUpdate.channel_id
            DRA_rp_TFTDisplayOn_TFTDisplayOn: accessed-variable=rp_TFTDisplayOn.TFTDisplayOn
            DRA_rp_custom_reset_CurrentUserID: accessed-variable=rp_custom_reset.CurrentUserID
            DRA_rp_custom_reset_CustomizeReset: accessed-variable=rp_custom_reset.CustomizeReset
            DRA_rp_custom_reset_SettingResetResult: accessed-variable=rp_custom_reset.SettingResetResult
        data-send-points:
          18 x access:
            DWA_pp_Illum_Transstep_Trans_Stepvlaue: accessed-variable=pp_Illum_Transstep.Trans_Stepvlaue
            DWA_pp_IlluminationDuty_DutyValue: accessed-variable=pp_IlluminationDuty.DutyValue
            DWA_pp_IlumDayNightRequired_ilumDNRequired: accessed-variable=pp_IlumDayNightRequired.ilumDNRequired
            DWA_pp_IlumDayNightStatus_illumDNStatus: accessed-variable=pp_IlumDayNightStatus.illumDNStatus
            DWA_pp_IlumStep_IllumStepValue: accessed-variable=pp_IlumStep.IllumStepValue
            DWA_pp_RGBStep_RGBStepValue: accessed-variable=pp_RGBStep.RGBStepValue
            DWA_pp_RHDW_Dbc_RHDW_Dbc: accessed-variable=pp_RHDW_Dbc.RHDW_Dbc
            DWA_pp_RHUP_Dbc_RHUP_Dbc: accessed-variable=pp_RHUP_Dbc.RHUP_Dbc
            DWA_pp_RheoSwRaw_Status_RawdataStatus: accessed-variable=pp_RheoSwRaw_Status.RawdataStatus
            DWA_pp_RheoSwStatus_SwitchStatus: accessed-variable=pp_RheoSwStatus.SwitchStatus
            DWA_pp_RheostatDayStep_RheostatDayStep: accessed-variable=pp_RheostatDayStep.RheostatDayStep
            DWA_pp_RheostatNightStep_RheostatNightStep: accessed-variable=pp_RheostatNightStep.RheostatNightStep
            DWA_pp_RheostatONSStatus_RheostatONSStatus: accessed-variable=pp_RheostatONSStatus.RheostatONSStatus
            DWA_pp_RheostatSwType_RheostatSwType: accessed-variable=pp_RheostatSwType.RheostatSwType
            DWA_pp_illumRheostatOnSTimer_Rheostat_OnSTime: accessed-variable=pp_illumRheostatOnSTimer.Rheostat_OnSTime
            DWA_pp_illumStarterstatus_StarterStatus_Out: accessed-variable=pp_illumStarterstatus.StarterStatus_Out
            DWA_pp_illum_rheostat_change_RheoUpdateVal: accessed-variable=pp_illum_rheostat_change.RheoUpdateVal
            DWA_pp_IllumCtrl_Ip_IllumCtrl_Ip_Data: accessed-variable=pp_IllumCtrl_Ip.IllumCtrl_Ip_Data
        409 x sync call:
          OA_rpIoHwAb_Din_GetAsyncRawInput: operation=rpIoHwAb_Din.GetAsyncRawInput
          OA_rpIoHwAb_Din_GetProcessedInput: operation=rpIoHwAb_Din.GetProcessedInput
          OA_rpIoHwAb_Din_GetSyncRawInput: operation=rpIoHwAb_Din.GetSyncRawInput
          OA_rpIoHwAb_Din_GetInputGroup: operation=rpIoHwAb_Din.GetInputGroup
          OA_rpUpdateDIMWarning_UpdateWarningStatus: operation=rpUpdateDIMWarning.UpdateWarningStatus
          OA_rp_CS_CanRx_RxCan_GetSignalValueU8Arr: operation=rp_CS_CanRx.RxCan_GetSignalValueU8Arr
          OA_rp_CS_CanRx_RxCan_SetSignalInitValue: operation=rp_CS_CanRx.RxCan_SetSignalInitValue
          OA_rp_CS_CanRx_RxCan_SetSignalInitValueU8Arr: operation=rp_CS_CanRx.RxCan_SetSignalInitValueU8Arr
          OA_rp_CS_CanRx_RxCan_SignalInvalidProcessingControl: operation=rp_CS_CanRx.RxCan_SignalInvalidProcessingControl
          OA_rp_CS_CanRx_RxCan_SignalMissingProcessingControl: operation=rp_CS_CanRx.RxCan_SignalMissingProcessingControl
          OA_rp_CS_CanRx_RxCan_SignalNRProcessingControl: operation=rp_CS_CanRx.RxCan_SignalNRProcessingControl
          OA_rp_CS_CanRx_RxCan_SignalGetJustRcvdStatus: operation=rp_CS_CanRx.RxCan_SignalGetJustRcvdStatus
          OA_rp_CS_CanRx_RxCan_SignalClearJustRcvdStatus: operation=rp_CS_CanRx.RxCan_SignalClearJustRcvdStatus
          OA_rp_CS_CanRx_RxCan_GetSignalValue: operation=rp_CS_CanRx.RxCan_GetSignalValue
          OA_rp_CS_MemAbsGet_Get_BsShare_SwUpdReflash_Element: operation=rp_CS_MemAbsGet.Get_BsShare_SwUpdReflash_Element
          OA_rp_CS_MemAbsGet_Get_BsShare_SwUpdFotaMode_Element: operation=rp_CS_MemAbsGet.Get_BsShare_SwUpdFotaMode_Element
          OA_rp_CS_MemAbsGet_Get_BsShare_SwUpdFotaFinPrint_Element: operation=rp_CS_MemAbsGet.Get_BsShare_SwUpdFotaFinPrint_Element
          OA_rp_CS_MemAbsGet_Get_BsShare_SwUpdFotaStatus_Element: operation=rp_CS_MemAbsGet.Get_BsShare_SwUpdFotaStatus_Element
          OA_rp_CS_MemAbsGet_Get_BsShare_SwUpdFotadecrypt_Element: operation=rp_CS_MemAbsGet.Get_BsShare_SwUpdFotadecrypt_Element
          OA_rp_CS_MemAbsGet_Get_BsShare_EcuPartNumber_Element: operation=rp_CS_MemAbsGet.Get_BsShare_EcuPartNumber_Element
          OA_rp_CS_MemAbsGet_Get_BsShare_VisteonPartNumber: operation=rp_CS_MemAbsGet.Get_BsShare_VisteonPartNumber
          OA_rp_CS_MemAbsGet_Get_BsShare_VisteonPCBPartNumber: operation=rp_CS_MemAbsGet.Get_BsShare_VisteonPCBPartNumber
          OA_rp_CS_MemAbsGet_Get_BsShare_ProductSerialNumber: operation=rp_CS_MemAbsGet.Get_BsShare_ProductSerialNumber
          OA_rp_CS_MemAbsGet_Get_BsShare_PCBSerialNumber: operation=rp_CS_MemAbsGet.Get_BsShare_PCBSerialNumber
          OA_rp_CS_MemAbsGet_Get_BsShare_SMTManufacturingDate: operation=rp_CS_MemAbsGet.Get_BsShare_SMTManufacturingDate
          OA_rp_CS_MemAbsGet_Get_BsShare_AssemblyManufacturingDate: operation=rp_CS_MemAbsGet.Get_BsShare_AssemblyManufacturingDate
          OA_rp_CS_MemAbsGet_Get_BsShare_SMTPlantNumber: operation=rp_CS_MemAbsGet.Get_BsShare_SMTPlantNumber
          OA_rp_CS_MemAbsGet_Get_BsShare_AssemblyPlantNumber: operation=rp_CS_MemAbsGet.Get_BsShare_AssemblyPlantNumber
          OA_rp_CS_MemAbsGet_Get_BsShare_HWModification: operation=rp_CS_MemAbsGet.Get_BsShare_HWModification
          OA_rp_CS_MemAbsGet_Get_BsShare_VisMeet_Element: operation=rp_CS_MemAbsGet.Get_BsShare_VisMeet_Element
          OA_rp_CS_MemAbsGet_Get_BsShare_VisMeet_EOLEntry_Element: operation=rp_CS_MemAbsGet.Get_BsShare_VisMeet_EOLEntry_Element
          OA_rp_CS_MemAbsGet_Get_BsShare_VehicleConfig_Element: operation=rp_CS_MemAbsGet.Get_BsShare_VehicleConfig_Element
          OA_rp_CS_MemAbsGet_Get_BsConst_SpeedoGauge_Element: operation=rp_CS_MemAbsGet.Get_BsConst_SpeedoGauge_Element
          OA_rp_CS_MemAbsGet_Get_BsConst_TachoGauge_Element: operation=rp_CS_MemAbsGet.Get_BsConst_TachoGauge_Element
          OA_rp_CS_MemAbsGet_Get_BsConst_FuelGauge_Element: operation=rp_CS_MemAbsGet.Get_BsConst_FuelGauge_Element
          OA_rp_CS_MemAbsGet_Get_BsConst_TempGauge_Element: operation=rp_CS_MemAbsGet.Get_BsConst_TempGauge_Element
          OA_rp_CS_MemAbsGet_Get_BsConst_PowerGauge_Element: operation=rp_CS_MemAbsGet.Get_BsConst_PowerGauge_Element
          OA_rp_CS_MemAbsGet_Get_BsConst_OilGauge_Element: operation=rp_CS_MemAbsGet.Get_BsConst_OilGauge_Element
          OA_rp_CS_MemAbsGet_Get_BsConst_TripComputer_Element: operation=rp_CS_MemAbsGet.Get_BsConst_TripComputer_Element
          OA_rp_CS_MemAbsGet_Get_BsConst_Audio_Element: operation=rp_CS_MemAbsGet.Get_BsConst_Audio_Element
          OA_rp_CS_MemAbsGet_Get_BsConst_Warning_Element: operation=rp_CS_MemAbsGet.Get_BsConst_Warning_Element
          OA_rp_CS_MemAbsGet_Get_BsConst_RealTimeClock_Element: operation=rp_CS_MemAbsGet.Get_BsConst_RealTimeClock_Element
          OA_rp_CS_MemAbsGet_Get_BsConst_Communication_Element: operation=rp_CS_MemAbsGet.Get_BsConst_Communication_Element
          OA_rp_CS_MemAbsGet_Get_BsConst_Power_Element: operation=rp_CS_MemAbsGet.Get_BsConst_Power_Element
          OA_rp_CS_MemAbsGet_Get_BsConst_ServiceReminder_Element: operation=rp_CS_MemAbsGet.Get_BsConst_ServiceReminder_Element
          OA_rp_CS_MemAbsGet_Get_BsConst_EngOffTimer_Element: operation=rp_CS_MemAbsGet.Get_BsConst_EngOffTimer_Element
          OA_rp_CS_MemAbsGet_Get_BsCys_Certicificate_Element: operation=rp_CS_MemAbsGet.Get_BsCys_Certicificate_Element
          OA_rp_CS_MemAbsGet_Get_RefCys_Certicificate_Element: operation=rp_CS_MemAbsGet.Get_RefCys_Certicificate_Element
          OA_rp_CS_MemAbsGet_Get_RefCys_Certicificate1_Element: operation=rp_CS_MemAbsGet.Get_RefCys_Certicificate1_Element
          OA_rp_CS_MemAbsGet_Get_BsRt_Odometer_Element: operation=rp_CS_MemAbsGet.Get_BsRt_Odometer_Element
          OA_rp_CS_MemAbsGet_Get_BsRt_SpeedoGauge_Element: operation=rp_CS_MemAbsGet.Get_BsRt_SpeedoGauge_Element
          OA_rp_CS_MemAbsGet_Get_BsRt_TachoGauge_Element: operation=rp_CS_MemAbsGet.Get_BsRt_TachoGauge_Element
          OA_rp_CS_MemAbsGet_Get_BsRt_FuelGauge_Element: operation=rp_CS_MemAbsGet.Get_BsRt_FuelGauge_Element
          OA_rp_CS_MemAbsGet_Get_BsRt_TempGauge_Element: operation=rp_CS_MemAbsGet.Get_BsRt_TempGauge_Element
          OA_rp_CS_MemAbsGet_Get_BsRt_PowerGauge_Element: operation=rp_CS_MemAbsGet.Get_BsRt_PowerGauge_Element
          OA_rp_CS_MemAbsGet_Get_BsRt_OilGauge_Element: operation=rp_CS_MemAbsGet.Get_BsRt_OilGauge_Element
          OA_rp_CS_MemAbsGet_Get_BsRt_TripComputer_Element: operation=rp_CS_MemAbsGet.Get_BsRt_TripComputer_Element
          OA_rp_CS_MemAbsGet_Get_BsRt_Warning_Element: operation=rp_CS_MemAbsGet.Get_BsRt_Warning_Element
          OA_rp_CS_MemAbsGet_Get_BsRt_RealTimeClock_Element: operation=rp_CS_MemAbsGet.Get_BsRt_RealTimeClock_Element
          OA_rp_CS_MemAbsGet_Get_BsRt_Personalization_Element: operation=rp_CS_MemAbsGet.Get_BsRt_Personalization_Element
          OA_rp_CS_MemAbsGet_Get_BsRt_Illumination_Element: operation=rp_CS_MemAbsGet.Get_BsRt_Illumination_Element
          OA_rp_CS_MemAbsGet_Get_BsRt_CusDlt_Element: operation=rp_CS_MemAbsGet.Get_BsRt_CusDlt_Element
          OA_rp_CS_MemAbsGet_Get_BsReten_Odometer_Element: operation=rp_CS_MemAbsGet.Get_BsReten_Odometer_Element
          OA_rp_CS_MemAbsGet_Get_BsReten_Gauges_Element: operation=rp_CS_MemAbsGet.Get_BsReten_Gauges_Element
          OA_rp_CS_MemAbsGet_Get_BsReten_Tripcomputer_Element: operation=rp_CS_MemAbsGet.Get_BsReten_Tripcomputer_Element
          OA_rp_CS_MemAbsGet_Get_BsReten_Illumination_Element: operation=rp_CS_MemAbsGet.Get_BsReten_Illumination_Element
          OA_rp_CS_MemAbsGet_Get_BsReten_Audio_Element: operation=rp_CS_MemAbsGet.Get_BsReten_Audio_Element
          OA_rp_CS_MemAbsGet_Get_BsReten_Warning_Element: operation=rp_CS_MemAbsGet.Get_BsReten_Warning_Element
          OA_rp_CS_MemAbsGet_Get_BsReten_RealTimeClock_Element: operation=rp_CS_MemAbsGet.Get_BsReten_RealTimeClock_Element
          OA_rp_CS_MemAbsGet_Get_BsReten_Communication_Element: operation=rp_CS_MemAbsGet.Get_BsReten_Communication_Element
          OA_rp_CS_MemAbsGet_Get_BsReten_Personalization_Element: operation=rp_CS_MemAbsGet.Get_BsReten_Personalization_Element
          OA_rp_CS_MemAbsGet_Get_BsReten_Power_Element: operation=rp_CS_MemAbsGet.Get_BsReten_Power_Element
          OA_rp_CS_MemAbsGet_Get_BsReten_Display_Element: operation=rp_CS_MemAbsGet.Get_BsReten_Display_Element
          OA_rp_CS_MemAbsGet_Get_BsDiag_ErrorRecord_Element: operation=rp_CS_MemAbsGet.Get_BsDiag_ErrorRecord_Element
          OA_rp_CS_MemAbsGet_Get_BsDiag_Dtc_Element: operation=rp_CS_MemAbsGet.Get_BsDiag_Dtc_Element
          OA_rp_CS_MemAbsSet_Set_BsShare_SwUpdReflash_Element: operation=rp_CS_MemAbsSet.Set_BsShare_SwUpdReflash_Element
          OA_rp_CS_MemAbsSet_Set_BsShare_SwUpdFotaMode_Element: operation=rp_CS_MemAbsSet.Set_BsShare_SwUpdFotaMode_Element
          OA_rp_CS_MemAbsSet_Set_BsShare_SwUpdFotaFinPrint_Element: operation=rp_CS_MemAbsSet.Set_BsShare_SwUpdFotaFinPrint_Element
          OA_rp_CS_MemAbsSet_Set_BsShare_SwUpdFotaStatus_Element: operation=rp_CS_MemAbsSet.Set_BsShare_SwUpdFotaStatus_Element
          OA_rp_CS_MemAbsSet_Set_BsShare_SwUpdFotadecrypt_Element: operation=rp_CS_MemAbsSet.Set_BsShare_SwUpdFotadecrypt_Element
          OA_rp_CS_MemAbsSet_Set_BsShare_EcuPartNumber_Element: operation=rp_CS_MemAbsSet.Set_BsShare_EcuPartNumber_Element
          OA_rp_CS_MemAbsSet_Set_BsShare_VisteonPartNumber: operation=rp_CS_MemAbsSet.Set_BsShare_VisteonPartNumber
          OA_rp_CS_MemAbsSet_Set_BsShare_VisteonPCBPartNumber: operation=rp_CS_MemAbsSet.Set_BsShare_VisteonPCBPartNumber
          OA_rp_CS_MemAbsSet_Set_BsShare_ProductSerialNumber: operation=rp_CS_MemAbsSet.Set_BsShare_ProductSerialNumber
          OA_rp_CS_MemAbsSet_Set_BsShare_PCBSerialNumber: operation=rp_CS_MemAbsSet.Set_BsShare_PCBSerialNumber
          OA_rp_CS_MemAbsSet_Set_BsShare_SMTManufacturingDate: operation=rp_CS_MemAbsSet.Set_BsShare_SMTManufacturingDate
          OA_rp_CS_MemAbsSet_Set_BsShare_AssemblyManufacturingDate: operation=rp_CS_MemAbsSet.Set_BsShare_AssemblyManufacturingDate
          OA_rp_CS_MemAbsSet_Set_BsShare_SMTPlantNumber: operation=rp_CS_MemAbsSet.Set_BsShare_SMTPlantNumber
          OA_rp_CS_MemAbsSet_Set_BsShare_AssemblyPlantNumber: operation=rp_CS_MemAbsSet.Set_BsShare_AssemblyPlantNumber
          OA_rp_CS_MemAbsSet_Set_BsShare_HWModification: operation=rp_CS_MemAbsSet.Set_BsShare_HWModification
          OA_rp_CS_MemAbsSet_Set_BsShare_VisMeet_Element: operation=rp_CS_MemAbsSet.Set_BsShare_VisMeet_Element
          OA_rp_CS_MemAbsSet_Set_BsShare_VisMeet_EOLEntry_Element: operation=rp_CS_MemAbsSet.Set_BsShare_VisMeet_EOLEntry_Element
          OA_rp_CS_MemAbsSet_Set_BsShare_VehicleConfig_Element: operation=rp_CS_MemAbsSet.Set_BsShare_VehicleConfig_Element
          OA_rp_CS_MemAbsSet_Set_BsConst_SpeedoGauge_Element: operation=rp_CS_MemAbsSet.Set_BsConst_SpeedoGauge_Element
          OA_rp_CS_MemAbsSet_Set_BsConst_TachoGauge_Element: operation=rp_CS_MemAbsSet.Set_BsConst_TachoGauge_Element
          OA_rp_CS_MemAbsSet_Set_BsConst_FuelGauge_Element: operation=rp_CS_MemAbsSet.Set_BsConst_FuelGauge_Element
          OA_rp_CS_MemAbsSet_Set_BsConst_TempGauge_Element: operation=rp_CS_MemAbsSet.Set_BsConst_TempGauge_Element
          OA_rp_CS_MemAbsSet_Set_BsConst_PowerGauge_Element: operation=rp_CS_MemAbsSet.Set_BsConst_PowerGauge_Element
          OA_rp_CS_MemAbsSet_Set_BsConst_OilGauge_Element: operation=rp_CS_MemAbsSet.Set_BsConst_OilGauge_Element
          OA_rp_CS_MemAbsSet_Set_BsConst_TripComputer_Element: operation=rp_CS_MemAbsSet.Set_BsConst_TripComputer_Element
          OA_rp_CS_MemAbsSet_Set_BsConst_Audio_Element: operation=rp_CS_MemAbsSet.Set_BsConst_Audio_Element
          OA_rp_CS_MemAbsSet_Set_BsConst_Warning_Element: operation=rp_CS_MemAbsSet.Set_BsConst_Warning_Element
          OA_rp_CS_MemAbsSet_Set_BsConst_RealTimeClock_Element: operation=rp_CS_MemAbsSet.Set_BsConst_RealTimeClock_Element
          OA_rp_CS_MemAbsSet_Set_BsConst_Communication_Element: operation=rp_CS_MemAbsSet.Set_BsConst_Communication_Element
          OA_rp_CS_MemAbsSet_Set_BsConst_Power_Element: operation=rp_CS_MemAbsSet.Set_BsConst_Power_Element
          OA_rp_CS_MemAbsSet_Set_BsConst_ServiceReminder_Element: operation=rp_CS_MemAbsSet.Set_BsConst_ServiceReminder_Element
          OA_rp_CS_MemAbsSet_Set_BsConst_EngOffTimer_Element: operation=rp_CS_MemAbsSet.Set_BsConst_EngOffTimer_Element
          OA_rp_CS_MemAbsSet_Set_BsCys_Certicificate_Element: operation=rp_CS_MemAbsSet.Set_BsCys_Certicificate_Element
          OA_rp_CS_MemAbsSet_Set_RefCys_Certicificate_Element: operation=rp_CS_MemAbsSet.Set_RefCys_Certicificate_Element
          OA_rp_CS_MemAbsSet_Set_RefCys_Certicificate1_Element: operation=rp_CS_MemAbsSet.Set_RefCys_Certicificate1_Element
          OA_rp_CS_MemAbsSet_Set_BsRt_Odometer_Element: operation=rp_CS_MemAbsSet.Set_BsRt_Odometer_Element
          OA_rp_CS_MemAbsSet_Set_BsRt_SpeedoGauge_Element: operation=rp_CS_MemAbsSet.Set_BsRt_SpeedoGauge_Element
          OA_rp_CS_MemAbsSet_Set_BsRt_TachoGauge_Element: operation=rp_CS_MemAbsSet.Set_BsRt_TachoGauge_Element
          OA_rp_CS_MemAbsSet_Set_BsRt_FuelGauge_Element: operation=rp_CS_MemAbsSet.Set_BsRt_FuelGauge_Element
          OA_rp_CS_MemAbsSet_Set_BsRt_TempGauge_Element: operation=rp_CS_MemAbsSet.Set_BsRt_TempGauge_Element
          OA_rp_CS_MemAbsSet_Set_BsRt_PowerGauge_Element: operation=rp_CS_MemAbsSet.Set_BsRt_PowerGauge_Element
          OA_rp_CS_MemAbsSet_Set_BsRt_OilGauge_Element: operation=rp_CS_MemAbsSet.Set_BsRt_OilGauge_Element
          OA_rp_CS_MemAbsSet_Set_BsRt_TripComputer_Element: operation=rp_CS_MemAbsSet.Set_BsRt_TripComputer_Element
          OA_rp_CS_MemAbsSet_Set_BsRt_Warning_Element: operation=rp_CS_MemAbsSet.Set_BsRt_Warning_Element
          OA_rp_CS_MemAbsSet_Set_BsRt_RealTimeClock_Element: operation=rp_CS_MemAbsSet.Set_BsRt_RealTimeClock_Element
          OA_rp_CS_MemAbsSet_Set_BsRt_Personalization_Element: operation=rp_CS_MemAbsSet.Set_BsRt_Personalization_Element
          OA_rp_CS_MemAbsSet_Set_BsRt_Illumination_Element: operation=rp_CS_MemAbsSet.Set_BsRt_Illumination_Element
          OA_rp_CS_MemAbsSet_Set_BsRt_CusDlt_Element: operation=rp_CS_MemAbsSet.Set_BsRt_CusDlt_Element
          OA_rp_CS_MemAbsSet_Set_BsReten_Odometer_Element: operation=rp_CS_MemAbsSet.Set_BsReten_Odometer_Element
          OA_rp_CS_MemAbsSet_Set_BsReten_Gauges_Element: operation=rp_CS_MemAbsSet.Set_BsReten_Gauges_Element
          OA_rp_CS_MemAbsSet_Set_BsReten_Tripcomputer_Element: operation=rp_CS_MemAbsSet.Set_BsReten_Tripcomputer_Element
          OA_rp_CS_MemAbsSet_Set_BsReten_Illumination_Element: operation=rp_CS_MemAbsSet.Set_BsReten_Illumination_Element
          OA_rp_CS_MemAbsSet_Set_BsReten_Audio_Element: operation=rp_CS_MemAbsSet.Set_BsReten_Audio_Element
          OA_rp_CS_MemAbsSet_Set_BsReten_Warning_Element: operation=rp_CS_MemAbsSet.Set_BsReten_Warning_Element
          OA_rp_CS_MemAbsSet_Set_BsReten_RealTimeClock_Element: operation=rp_CS_MemAbsSet.Set_BsReten_RealTimeClock_Element
          OA_rp_CS_MemAbsSet_Set_BsReten_Communication_Element: operation=rp_CS_MemAbsSet.Set_BsReten_Communication_Element
          OA_rp_CS_MemAbsSet_Set_BsReten_Personalization_Element: operation=rp_CS_MemAbsSet.Set_BsReten_Personalization_Element
          OA_rp_CS_MemAbsSet_Set_BsReten_Power_Element: operation=rp_CS_MemAbsSet.Set_BsReten_Power_Element
          OA_rp_CS_MemAbsSet_Set_BsReten_Display_Element: operation=rp_CS_MemAbsSet.Set_BsReten_Display_Element
          OA_rp_CS_MemAbsSet_Set_BsDiag_ErrorRecord_Element: operation=rp_CS_MemAbsSet.Set_BsDiag_ErrorRecord_Element
          OA_rp_CS_MemAbsSet_Set_BsDiag_Dtc_Element: operation=rp_CS_MemAbsSet.Set_BsDiag_Dtc_Element
          OA_rp_CS_RxCanMdl_RxCan_GetSignalValueU8Arr: operation=rp_CS_RxCanMdl.RxCan_GetSignalValueU8Arr
          OA_rp_CS_RxCanMdl_RxCan_SetSignalInitValue: operation=rp_CS_RxCanMdl.RxCan_SetSignalInitValue
          OA_rp_CS_RxCanMdl_RxCan_SetSignalInitValueU8Arr: operation=rp_CS_RxCanMdl.RxCan_SetSignalInitValueU8Arr
          OA_rp_CS_RxCanMdl_RxCan_SignalInvalidProcessingControl: operation=rp_CS_RxCanMdl.RxCan_SignalInvalidProcessingControl
          OA_rp_CS_RxCanMdl_RxCan_SignalMissingProcessingControl: operation=rp_CS_RxCanMdl.RxCan_SignalMissingProcessingControl
          OA_rp_CS_RxCanMdl_RxCan_SignalNRProcessingControl: operation=rp_CS_RxCanMdl.RxCan_SignalNRProcessingControl
          OA_rp_CS_RxCanMdl_RxCan_SignalGetJustRcvdStatus: operation=rp_CS_RxCanMdl.RxCan_SignalGetJustRcvdStatus
          OA_rp_CS_RxCanMdl_RxCan_SignalClearJustRcvdStatus: operation=rp_CS_RxCanMdl.RxCan_SignalClearJustRcvdStatus
          OA_rp_CS_RxCanMdl_RxCan_GetSignalValue: operation=rp_CS_RxCanMdl.RxCan_GetSignalValue
          OA_rp_Current_duty_GetPwmCurrentDuty: operation=rp_Current_duty.GetPwmCurrentDuty
          OA_rp_GetNVM_IlluminationData_Get_BsShare_SwUpdReflash_Element: operation=rp_GetNVM_IlluminationData.Get_BsShare_SwUpdReflash_Element
          OA_rp_GetNVM_IlluminationData_Get_BsShare_SwUpdFotaMode_Element: operation=rp_GetNVM_IlluminationData.Get_BsShare_SwUpdFotaMode_Element
          OA_rp_GetNVM_IlluminationData_Get_BsShare_SwUpdFotaFinPrint_Element: operation=rp_GetNVM_IlluminationData.Get_BsShare_SwUpdFotaFinPrint_Element
          OA_rp_GetNVM_IlluminationData_Get_BsShare_SwUpdFotaStatus_Element: operation=rp_GetNVM_IlluminationData.Get_BsShare_SwUpdFotaStatus_Element
          OA_rp_GetNVM_IlluminationData_Get_BsShare_SwUpdFotadecrypt_Element: operation=rp_GetNVM_IlluminationData.Get_BsShare_SwUpdFotadecrypt_Element
          OA_rp_GetNVM_IlluminationData_Get_BsShare_EcuPartNumber_Element: operation=rp_GetNVM_IlluminationData.Get_BsShare_EcuPartNumber_Element
          OA_rp_GetNVM_IlluminationData_Get_BsShare_VisteonPartNumber: operation=rp_GetNVM_IlluminationData.Get_BsShare_VisteonPartNumber
          OA_rp_GetNVM_IlluminationData_Get_BsShare_VisteonPCBPartNumber: operation=rp_GetNVM_IlluminationData.Get_BsShare_VisteonPCBPartNumber
          OA_rp_GetNVM_IlluminationData_Get_BsShare_ProductSerialNumber: operation=rp_GetNVM_IlluminationData.Get_BsShare_ProductSerialNumber
          OA_rp_GetNVM_IlluminationData_Get_BsShare_PCBSerialNumber: operation=rp_GetNVM_IlluminationData.Get_BsShare_PCBSerialNumber
          OA_rp_GetNVM_IlluminationData_Get_BsShare_SMTManufacturingDate: operation=rp_GetNVM_IlluminationData.Get_BsShare_SMTManufacturingDate
          OA_rp_GetNVM_IlluminationData_Get_BsShare_AssemblyManufacturingDate: operation=rp_GetNVM_IlluminationData.Get_BsShare_AssemblyManufacturingDate
          OA_rp_GetNVM_IlluminationData_Get_BsShare_SMTPlantNumber: operation=rp_GetNVM_IlluminationData.Get_BsShare_SMTPlantNumber
          OA_rp_GetNVM_IlluminationData_Get_BsShare_AssemblyPlantNumber: operation=rp_GetNVM_IlluminationData.Get_BsShare_AssemblyPlantNumber
          OA_rp_GetNVM_IlluminationData_Get_BsShare_HWModification: operation=rp_GetNVM_IlluminationData.Get_BsShare_HWModification
          OA_rp_GetNVM_IlluminationData_Get_BsShare_VisMeet_Element: operation=rp_GetNVM_IlluminationData.Get_BsShare_VisMeet_Element
          OA_rp_GetNVM_IlluminationData_Get_BsShare_VisMeet_EOLEntry_Element: operation=rp_GetNVM_IlluminationData.Get_BsShare_VisMeet_EOLEntry_Element
          OA_rp_GetNVM_IlluminationData_Get_BsShare_VehicleConfig_Element: operation=rp_GetNVM_IlluminationData.Get_BsShare_VehicleConfig_Element
          OA_rp_GetNVM_IlluminationData_Get_BsConst_SpeedoGauge_Element: operation=rp_GetNVM_IlluminationData.Get_BsConst_SpeedoGauge_Element
          OA_rp_GetNVM_IlluminationData_Get_BsConst_TachoGauge_Element: operation=rp_GetNVM_IlluminationData.Get_BsConst_TachoGauge_Element
          OA_rp_GetNVM_IlluminationData_Get_BsConst_FuelGauge_Element: operation=rp_GetNVM_IlluminationData.Get_BsConst_FuelGauge_Element
          OA_rp_GetNVM_IlluminationData_Get_BsConst_TempGauge_Element: operation=rp_GetNVM_IlluminationData.Get_BsConst_TempGauge_Element
          OA_rp_GetNVM_IlluminationData_Get_BsConst_PowerGauge_Element: operation=rp_GetNVM_IlluminationData.Get_BsConst_PowerGauge_Element
          OA_rp_GetNVM_IlluminationData_Get_BsConst_OilGauge_Element: operation=rp_GetNVM_IlluminationData.Get_BsConst_OilGauge_Element
          OA_rp_GetNVM_IlluminationData_Get_BsConst_TripComputer_Element: operation=rp_GetNVM_IlluminationData.Get_BsConst_TripComputer_Element
          OA_rp_GetNVM_IlluminationData_Get_BsConst_Audio_Element: operation=rp_GetNVM_IlluminationData.Get_BsConst_Audio_Element
          OA_rp_GetNVM_IlluminationData_Get_BsConst_Warning_Element: operation=rp_GetNVM_IlluminationData.Get_BsConst_Warning_Element
          OA_rp_GetNVM_IlluminationData_Get_BsConst_RealTimeClock_Element: operation=rp_GetNVM_IlluminationData.Get_BsConst_RealTimeClock_Element
          OA_rp_GetNVM_IlluminationData_Get_BsConst_Communication_Element: operation=rp_GetNVM_IlluminationData.Get_BsConst_Communication_Element
          OA_rp_GetNVM_IlluminationData_Get_BsConst_Power_Element: operation=rp_GetNVM_IlluminationData.Get_BsConst_Power_Element
          OA_rp_GetNVM_IlluminationData_Get_BsConst_ServiceReminder_Element: operation=rp_GetNVM_IlluminationData.Get_BsConst_ServiceReminder_Element
          OA_rp_GetNVM_IlluminationData_Get_BsConst_EngOffTimer_Element: operation=rp_GetNVM_IlluminationData.Get_BsConst_EngOffTimer_Element
          OA_rp_GetNVM_IlluminationData_Get_BsCys_Certicificate_Element: operation=rp_GetNVM_IlluminationData.Get_BsCys_Certicificate_Element
          OA_rp_GetNVM_IlluminationData_Get_RefCys_Certicificate_Element: operation=rp_GetNVM_IlluminationData.Get_RefCys_Certicificate_Element
          OA_rp_GetNVM_IlluminationData_Get_RefCys_Certicificate1_Element: operation=rp_GetNVM_IlluminationData.Get_RefCys_Certicificate1_Element
          OA_rp_GetNVM_IlluminationData_Get_BsRt_Odometer_Element: operation=rp_GetNVM_IlluminationData.Get_BsRt_Odometer_Element
          OA_rp_GetNVM_IlluminationData_Get_BsRt_SpeedoGauge_Element: operation=rp_GetNVM_IlluminationData.Get_BsRt_SpeedoGauge_Element
          OA_rp_GetNVM_IlluminationData_Get_BsRt_TachoGauge_Element: operation=rp_GetNVM_IlluminationData.Get_BsRt_TachoGauge_Element
          OA_rp_GetNVM_IlluminationData_Get_BsRt_FuelGauge_Element: operation=rp_GetNVM_IlluminationData.Get_BsRt_FuelGauge_Element
          OA_rp_GetNVM_IlluminationData_Get_BsRt_TempGauge_Element: operation=rp_GetNVM_IlluminationData.Get_BsRt_TempGauge_Element
          OA_rp_GetNVM_IlluminationData_Get_BsRt_PowerGauge_Element: operation=rp_GetNVM_IlluminationData.Get_BsRt_PowerGauge_Element
          OA_rp_GetNVM_IlluminationData_Get_BsRt_OilGauge_Element: operation=rp_GetNVM_IlluminationData.Get_BsRt_OilGauge_Element
          OA_rp_GetNVM_IlluminationData_Get_BsRt_TripComputer_Element: operation=rp_GetNVM_IlluminationData.Get_BsRt_TripComputer_Element
          OA_rp_GetNVM_IlluminationData_Get_BsRt_Warning_Element: operation=rp_GetNVM_IlluminationData.Get_BsRt_Warning_Element
          OA_rp_GetNVM_IlluminationData_Get_BsRt_RealTimeClock_Element: operation=rp_GetNVM_IlluminationData.Get_BsRt_RealTimeClock_Element
          OA_rp_GetNVM_IlluminationData_Get_BsRt_Personalization_Element: operation=rp_GetNVM_IlluminationData.Get_BsRt_Personalization_Element
          OA_rp_GetNVM_IlluminationData_Get_BsRt_Illumination_Element: operation=rp_GetNVM_IlluminationData.Get_BsRt_Illumination_Element
          OA_rp_GetNVM_IlluminationData_Get_BsRt_CusDlt_Element: operation=rp_GetNVM_IlluminationData.Get_BsRt_CusDlt_Element
          OA_rp_GetNVM_IlluminationData_Get_BsReten_Odometer_Element: operation=rp_GetNVM_IlluminationData.Get_BsReten_Odometer_Element
          OA_rp_GetNVM_IlluminationData_Get_BsReten_Gauges_Element: operation=rp_GetNVM_IlluminationData.Get_BsReten_Gauges_Element
          OA_rp_GetNVM_IlluminationData_Get_BsReten_Tripcomputer_Element: operation=rp_GetNVM_IlluminationData.Get_BsReten_Tripcomputer_Element
          OA_rp_GetNVM_IlluminationData_Get_BsReten_Illumination_Element: operation=rp_GetNVM_IlluminationData.Get_BsReten_Illumination_Element
          OA_rp_GetNVM_IlluminationData_Get_BsReten_Audio_Element: operation=rp_GetNVM_IlluminationData.Get_BsReten_Audio_Element
          OA_rp_GetNVM_IlluminationData_Get_BsReten_Warning_Element: operation=rp_GetNVM_IlluminationData.Get_BsReten_Warning_Element
          OA_rp_GetNVM_IlluminationData_Get_BsReten_RealTimeClock_Element: operation=rp_GetNVM_IlluminationData.Get_BsReten_RealTimeClock_Element
          OA_rp_GetNVM_IlluminationData_Get_BsReten_Communication_Element: operation=rp_GetNVM_IlluminationData.Get_BsReten_Communication_Element
          OA_rp_GetNVM_IlluminationData_Get_BsReten_Personalization_Element: operation=rp_GetNVM_IlluminationData.Get_BsReten_Personalization_Element
          OA_rp_GetNVM_IlluminationData_Get_BsReten_Power_Element: operation=rp_GetNVM_IlluminationData.Get_BsReten_Power_Element
          OA_rp_GetNVM_IlluminationData_Get_BsReten_Display_Element: operation=rp_GetNVM_IlluminationData.Get_BsReten_Display_Element
          OA_rp_GetNVM_IlluminationData_Get_BsDiag_ErrorRecord_Element: operation=rp_GetNVM_IlluminationData.Get_BsDiag_ErrorRecord_Element
          OA_rp_GetNVM_IlluminationData_Get_BsDiag_Dtc_Element: operation=rp_GetNVM_IlluminationData.Get_BsDiag_Dtc_Element
          OA_rp_Get_Variant_Cfg_Get_Variant_Config_State: operation=rp_Get_Variant_Cfg.Get_Variant_Config_State
          OA_rp_ILL_ReadyToSleep_SWCSleepStatus: operation=rp_ILL_ReadyToSleep.SWCSleepStatus
          OA_rp_IoHwAb_ADC_GetAsyncRawAdc: operation=rp_IoHwAb_ADC.GetAsyncRawAdc
          OA_rp_IoHwAb_ADC_GetSyncRawAdc: operation=rp_IoHwAb_ADC.GetSyncRawAdc
          OA_rp_IoHwAb_ADC_GetProcessedAdc: operation=rp_IoHwAb_ADC.GetProcessedAdc
          OA_rp_PwmWithTime_GetPwmWithTime: operation=rp_PwmWithTime.GetPwmWithTime
          OA_rp_PwmWithTimeExp_GetPwmWithTimeExp: operation=rp_PwmWithTimeExp.GetPwmWithTimeExp
          OA_rp_SetNVM_IlluminationData_Set_BsShare_SwUpdReflash_Element: operation=rp_SetNVM_IlluminationData.Set_BsShare_SwUpdReflash_Element
          OA_rp_SetNVM_IlluminationData_Set_BsShare_SwUpdFotaMode_Element: operation=rp_SetNVM_IlluminationData.Set_BsShare_SwUpdFotaMode_Element
          OA_rp_SetNVM_IlluminationData_Set_BsShare_SwUpdFotaFinPrint_Element: operation=rp_SetNVM_IlluminationData.Set_BsShare_SwUpdFotaFinPrint_Element
          OA_rp_SetNVM_IlluminationData_Set_BsShare_SwUpdFotaStatus_Element: operation=rp_SetNVM_IlluminationData.Set_BsShare_SwUpdFotaStatus_Element
          OA_rp_SetNVM_IlluminationData_Set_BsShare_SwUpdFotadecrypt_Element: operation=rp_SetNVM_IlluminationData.Set_BsShare_SwUpdFotadecrypt_Element
          OA_rp_SetNVM_IlluminationData_Set_BsShare_EcuPartNumber_Element: operation=rp_SetNVM_IlluminationData.Set_BsShare_EcuPartNumber_Element
          OA_rp_SetNVM_IlluminationData_Set_BsShare_VisteonPartNumber: operation=rp_SetNVM_IlluminationData.Set_BsShare_VisteonPartNumber
          OA_rp_SetNVM_IlluminationData_Set_BsShare_VisteonPCBPartNumber: operation=rp_SetNVM_IlluminationData.Set_BsShare_VisteonPCBPartNumber
          OA_rp_SetNVM_IlluminationData_Set_BsShare_ProductSerialNumber: operation=rp_SetNVM_IlluminationData.Set_BsShare_ProductSerialNumber
          OA_rp_SetNVM_IlluminationData_Set_BsShare_PCBSerialNumber: operation=rp_SetNVM_IlluminationData.Set_BsShare_PCBSerialNumber
          OA_rp_SetNVM_IlluminationData_Set_BsShare_SMTManufacturingDate: operation=rp_SetNVM_IlluminationData.Set_BsShare_SMTManufacturingDate
          OA_rp_SetNVM_IlluminationData_Set_BsShare_AssemblyManufacturingDate: operation=rp_SetNVM_IlluminationData.Set_BsShare_AssemblyManufacturingDate
          OA_rp_SetNVM_IlluminationData_Set_BsShare_SMTPlantNumber: operation=rp_SetNVM_IlluminationData.Set_BsShare_SMTPlantNumber
          OA_rp_SetNVM_IlluminationData_Set_BsShare_AssemblyPlantNumber: operation=rp_SetNVM_IlluminationData.Set_BsShare_AssemblyPlantNumber
          OA_rp_SetNVM_IlluminationData_Set_BsShare_HWModification: operation=rp_SetNVM_IlluminationData.Set_BsShare_HWModification
          OA_rp_SetNVM_IlluminationData_Set_BsShare_VisMeet_Element: operation=rp_SetNVM_IlluminationData.Set_BsShare_VisMeet_Element
          OA_rp_SetNVM_IlluminationData_Set_BsShare_VisMeet_EOLEntry_Element: operation=rp_SetNVM_IlluminationData.Set_BsShare_VisMeet_EOLEntry_Element
          OA_rp_SetNVM_IlluminationData_Set_BsShare_VehicleConfig_Element: operation=rp_SetNVM_IlluminationData.Set_BsShare_VehicleConfig_Element
          OA_rp_SetNVM_IlluminationData_Set_BsConst_SpeedoGauge_Element: operation=rp_SetNVM_IlluminationData.Set_BsConst_SpeedoGauge_Element
          OA_rp_SetNVM_IlluminationData_Set_BsConst_TachoGauge_Element: operation=rp_SetNVM_IlluminationData.Set_BsConst_TachoGauge_Element
          OA_rp_SetNVM_IlluminationData_Set_BsConst_FuelGauge_Element: operation=rp_SetNVM_IlluminationData.Set_BsConst_FuelGauge_Element
          OA_rp_SetNVM_IlluminationData_Set_BsConst_TempGauge_Element: operation=rp_SetNVM_IlluminationData.Set_BsConst_TempGauge_Element
          OA_rp_SetNVM_IlluminationData_Set_BsConst_PowerGauge_Element: operation=rp_SetNVM_IlluminationData.Set_BsConst_PowerGauge_Element
          OA_rp_SetNVM_IlluminationData_Set_BsConst_OilGauge_Element: operation=rp_SetNVM_IlluminationData.Set_BsConst_OilGauge_Element
          OA_rp_SetNVM_IlluminationData_Set_BsConst_TripComputer_Element: operation=rp_SetNVM_IlluminationData.Set_BsConst_TripComputer_Element
          OA_rp_SetNVM_IlluminationData_Set_BsConst_Audio_Element: operation=rp_SetNVM_IlluminationData.Set_BsConst_Audio_Element
          OA_rp_SetNVM_IlluminationData_Set_BsConst_Warning_Element: operation=rp_SetNVM_IlluminationData.Set_BsConst_Warning_Element
          OA_rp_SetNVM_IlluminationData_Set_BsConst_RealTimeClock_Element: operation=rp_SetNVM_IlluminationData.Set_BsConst_RealTimeClock_Element
          OA_rp_SetNVM_IlluminationData_Set_BsConst_Communication_Element: operation=rp_SetNVM_IlluminationData.Set_BsConst_Communication_Element
          OA_rp_SetNVM_IlluminationData_Set_BsConst_Power_Element: operation=rp_SetNVM_IlluminationData.Set_BsConst_Power_Element
          OA_rp_SetNVM_IlluminationData_Set_BsConst_ServiceReminder_Element: operation=rp_SetNVM_IlluminationData.Set_BsConst_ServiceReminder_Element
          OA_rp_SetNVM_IlluminationData_Set_BsConst_EngOffTimer_Element: operation=rp_SetNVM_IlluminationData.Set_BsConst_EngOffTimer_Element
          OA_rp_SetNVM_IlluminationData_Set_BsCys_Certicificate_Element: operation=rp_SetNVM_IlluminationData.Set_BsCys_Certicificate_Element
          OA_rp_SetNVM_IlluminationData_Set_RefCys_Certicificate_Element: operation=rp_SetNVM_IlluminationData.Set_RefCys_Certicificate_Element
          OA_rp_SetNVM_IlluminationData_Set_RefCys_Certicificate1_Element: operation=rp_SetNVM_IlluminationData.Set_RefCys_Certicificate1_Element
          OA_rp_SetNVM_IlluminationData_Set_BsRt_Odometer_Element: operation=rp_SetNVM_IlluminationData.Set_BsRt_Odometer_Element
          OA_rp_SetNVM_IlluminationData_Set_BsRt_SpeedoGauge_Element: operation=rp_SetNVM_IlluminationData.Set_BsRt_SpeedoGauge_Element
          OA_rp_SetNVM_IlluminationData_Set_BsRt_TachoGauge_Element: operation=rp_SetNVM_IlluminationData.Set_BsRt_TachoGauge_Element
          OA_rp_SetNVM_IlluminationData_Set_BsRt_FuelGauge_Element: operation=rp_SetNVM_IlluminationData.Set_BsRt_FuelGauge_Element
          OA_rp_SetNVM_IlluminationData_Set_BsRt_TempGauge_Element: operation=rp_SetNVM_IlluminationData.Set_BsRt_TempGauge_Element
          OA_rp_SetNVM_IlluminationData_Set_BsRt_PowerGauge_Element: operation=rp_SetNVM_IlluminationData.Set_BsRt_PowerGauge_Element
          OA_rp_SetNVM_IlluminationData_Set_BsRt_OilGauge_Element: operation=rp_SetNVM_IlluminationData.Set_BsRt_OilGauge_Element
          OA_rp_SetNVM_IlluminationData_Set_BsRt_TripComputer_Element: operation=rp_SetNVM_IlluminationData.Set_BsRt_TripComputer_Element
          OA_rp_SetNVM_IlluminationData_Set_BsRt_Warning_Element: operation=rp_SetNVM_IlluminationData.Set_BsRt_Warning_Element
          OA_rp_SetNVM_IlluminationData_Set_BsRt_RealTimeClock_Element: operation=rp_SetNVM_IlluminationData.Set_BsRt_RealTimeClock_Element
          OA_rp_SetNVM_IlluminationData_Set_BsRt_Personalization_Element: operation=rp_SetNVM_IlluminationData.Set_BsRt_Personalization_Element
          OA_rp_SetNVM_IlluminationData_Set_BsRt_Illumination_Element: operation=rp_SetNVM_IlluminationData.Set_BsRt_Illumination_Element
          OA_rp_SetNVM_IlluminationData_Set_BsRt_CusDlt_Element: operation=rp_SetNVM_IlluminationData.Set_BsRt_CusDlt_Element
          OA_rp_SetNVM_IlluminationData_Set_BsReten_Odometer_Element: operation=rp_SetNVM_IlluminationData.Set_BsReten_Odometer_Element
          OA_rp_SetNVM_IlluminationData_Set_BsReten_Gauges_Element: operation=rp_SetNVM_IlluminationData.Set_BsReten_Gauges_Element
          OA_rp_SetNVM_IlluminationData_Set_BsReten_Tripcomputer_Element: operation=rp_SetNVM_IlluminationData.Set_BsReten_Tripcomputer_Element
          OA_rp_SetNVM_IlluminationData_Set_BsReten_Illumination_Element: operation=rp_SetNVM_IlluminationData.Set_BsReten_Illumination_Element
          OA_rp_SetNVM_IlluminationData_Set_BsReten_Audio_Element: operation=rp_SetNVM_IlluminationData.Set_BsReten_Audio_Element
          OA_rp_SetNVM_IlluminationData_Set_BsReten_Warning_Element: operation=rp_SetNVM_IlluminationData.Set_BsReten_Warning_Element
          OA_rp_SetNVM_IlluminationData_Set_BsReten_RealTimeClock_Element: operation=rp_SetNVM_IlluminationData.Set_BsReten_RealTimeClock_Element
          OA_rp_SetNVM_IlluminationData_Set_BsReten_Communication_Element: operation=rp_SetNVM_IlluminationData.Set_BsReten_Communication_Element
          OA_rp_SetNVM_IlluminationData_Set_BsReten_Personalization_Element: operation=rp_SetNVM_IlluminationData.Set_BsReten_Personalization_Element
          OA_rp_SetNVM_IlluminationData_Set_BsReten_Power_Element: operation=rp_SetNVM_IlluminationData.Set_BsReten_Power_Element
          OA_rp_SetNVM_IlluminationData_Set_BsReten_Display_Element: operation=rp_SetNVM_IlluminationData.Set_BsReten_Display_Element
          OA_rp_SetNVM_IlluminationData_Set_BsDiag_ErrorRecord_Element: operation=rp_SetNVM_IlluminationData.Set_BsDiag_ErrorRecord_Element
          OA_rp_SetNVM_IlluminationData_Set_BsDiag_Dtc_Element: operation=rp_SetNVM_IlluminationData.Set_BsDiag_Dtc_Element
          OA_rp_UpdatePwmDirect_GetPwmDirect: operation=rp_UpdatePwmDirect.GetPwmDirect
          OA_rp_Variant_Status_GetVariant_Status: operation=rp_Variant_Status.GetVariant_Status
          OA_rp_CS_MemAbsGet_Get_BsConst_Compensation_Line_Slope_m: operation=rp_CS_MemAbsGet.Get_BsConst_Compensation_Line_Slope_m
          OA_rp_CS_MemAbsGet_Get_BsConst_Compensation_Line_Shift_b: operation=rp_CS_MemAbsGet.Get_BsConst_Compensation_Line_Shift_b
          OA_rp_CS_MemAbsGet_Get_BsConst_Lookup_Curve_HotSpot_Coef_X: operation=rp_CS_MemAbsGet.Get_BsConst_Lookup_Curve_HotSpot_Coef_X
          OA_rp_CS_MemAbsGet_Get_BsConst_Lookup_Curve_HotSpot_Coef_Y: operation=rp_CS_MemAbsGet.Get_BsConst_Lookup_Curve_HotSpot_Coef_Y
          OA_rp_CS_MemAbsGet_Get_BsConst_Temp_Threshold_Hysteresis_Derating: operation=rp_CS_MemAbsGet.Get_BsConst_Temp_Threshold_Hysteresis_Derating
          OA_rp_CS_MemAbsGet_Get_BsConst_Derating_Backlight_Disable: operation=rp_CS_MemAbsGet.Get_BsConst_Derating_Backlight_Disable
          OA_rp_CS_MemAbsGet_Get_BsConst_Temperature_Sensor_Conv: operation=rp_CS_MemAbsGet.Get_BsConst_Temperature_Sensor_Conv
          OA_rp_CS_MemAbsGet_Get_BsConst_PCB_Temperature_Sensor_Conv: operation=rp_CS_MemAbsGet.Get_BsConst_PCB_Temperature_Sensor_Conv
          OA_rp_CS_MemAbsGet_Get_BsConst_Display_Illum_Max_Level: operation=rp_CS_MemAbsGet.Get_BsConst_Display_Illum_Max_Level
          OA_rp_CS_MemAbsGet_Get_BsConst_PWM_boost_bypass_duty: operation=rp_CS_MemAbsGet.Get_BsConst_PWM_boost_bypass_duty
          OA_rp_CS_MemAbsGet_Get_BsConst_BsConst_Illumination_ReservedByte: operation=rp_CS_MemAbsGet.Get_BsConst_BsConst_Illumination_ReservedByte
          OA_rp_CS_MemAbsGet_Get_BsConst_Compensation_Line_Slope_m_SafeCopy1: operation=rp_CS_MemAbsGet.Get_BsConst_Compensation_Line_Slope_m_SafeCopy1
          OA_rp_CS_MemAbsGet_Get_BsConst_Compensation_Line_Shift_b_SafeCopy1: operation=rp_CS_MemAbsGet.Get_BsConst_Compensation_Line_Shift_b_SafeCopy1
          OA_rp_CS_MemAbsGet_Get_BsConst_Lookup_Curve_HotSpot_Coef_X_SafeCopy1: operation=rp_CS_MemAbsGet.Get_BsConst_Lookup_Curve_HotSpot_Coef_X_SafeCopy1
          OA_rp_CS_MemAbsGet_Get_BsConst_Lookup_Curve_HotSpot_Coef_Y_SafeCopy1: operation=rp_CS_MemAbsGet.Get_BsConst_Lookup_Curve_HotSpot_Coef_Y_SafeCopy1
          OA_rp_CS_MemAbsGet_Get_BsConst_Temp_Threshold_Hysteresis_Derating_SafeCopy1: operation=rp_CS_MemAbsGet.Get_BsConst_Temp_Threshold_Hysteresis_Derating_SafeCopy1
          OA_rp_CS_MemAbsGet_Get_BsConst_Derating_Backlight_Disable_SafeCopy1: operation=rp_CS_MemAbsGet.Get_BsConst_Derating_Backlight_Disable_SafeCopy1
          OA_rp_CS_MemAbsGet_Get_BsConst_Temperature_Sensor_Conv_SafeCopy1: operation=rp_CS_MemAbsGet.Get_BsConst_Temperature_Sensor_Conv_SafeCopy1
          OA_rp_CS_MemAbsGet_Get_BsConst_PCB_Temperature_Sensor_Conv_SafeCopy1: operation=rp_CS_MemAbsGet.Get_BsConst_PCB_Temperature_Sensor_Conv_SafeCopy1
          OA_rp_CS_MemAbsGet_Get_BsConst_Display_Illum_Max_Level_SafeCopy1: operation=rp_CS_MemAbsGet.Get_BsConst_Display_Illum_Max_Level_SafeCopy1
          OA_rp_CS_MemAbsGet_Get_BsConst_PWM_boost_bypass_duty_SafeCopy1: operation=rp_CS_MemAbsGet.Get_BsConst_PWM_boost_bypass_duty_SafeCopy1
          OA_rp_CS_MemAbsGet_Get_BsConst_BsConst_Illumination_ReservedByte_SafeCopy1: operation=rp_CS_MemAbsGet.Get_BsConst_BsConst_Illumination_ReservedByte_SafeCopy1
          OA_rp_CS_MemAbsGet_Get_BsConst_Compensation_Line_Slope_m_SafeCopy2: operation=rp_CS_MemAbsGet.Get_BsConst_Compensation_Line_Slope_m_SafeCopy2
          OA_rp_CS_MemAbsGet_Get_BsConst_Compensation_Line_Shift_b_SafeCopy2: operation=rp_CS_MemAbsGet.Get_BsConst_Compensation_Line_Shift_b_SafeCopy2
          OA_rp_CS_MemAbsGet_Get_BsConst_Lookup_Curve_HotSpot_Coef_X_SafeCopy2: operation=rp_CS_MemAbsGet.Get_BsConst_Lookup_Curve_HotSpot_Coef_X_SafeCopy2
          OA_rp_CS_MemAbsGet_Get_BsConst_Lookup_Curve_HotSpot_Coef_Y_SafeCopy2: operation=rp_CS_MemAbsGet.Get_BsConst_Lookup_Curve_HotSpot_Coef_Y_SafeCopy2
          OA_rp_CS_MemAbsGet_Get_BsConst_Temp_Threshold_Hysteresis_Derating_SafeCopy2: operation=rp_CS_MemAbsGet.Get_BsConst_Temp_Threshold_Hysteresis_Derating_SafeCopy2
          OA_rp_CS_MemAbsGet_Get_BsConst_Derating_Backlight_Disable_SafeCopy2: operation=rp_CS_MemAbsGet.Get_BsConst_Derating_Backlight_Disable_SafeCopy2
          OA_rp_CS_MemAbsGet_Get_BsConst_Temperature_Sensor_Conv_SafeCopy2: operation=rp_CS_MemAbsGet.Get_BsConst_Temperature_Sensor_Conv_SafeCopy2
          OA_rp_CS_MemAbsGet_Get_BsConst_PCB_Temperature_Sensor_Conv_SafeCopy2: operation=rp_CS_MemAbsGet.Get_BsConst_PCB_Temperature_Sensor_Conv_SafeCopy2
          OA_rp_CS_MemAbsGet_Get_BsConst_Display_Illum_Max_Level_SafeCopy2: operation=rp_CS_MemAbsGet.Get_BsConst_Display_Illum_Max_Level_SafeCopy2
          OA_rp_CS_MemAbsGet_Get_BsConst_PWM_boost_bypass_duty_SafeCopy2: operation=rp_CS_MemAbsGet.Get_BsConst_PWM_boost_bypass_duty_SafeCopy2
          OA_rp_CS_MemAbsGet_Get_BsConst_BsConst_Illumination_ReservedByte_SafeCopy2: operation=rp_CS_MemAbsGet.Get_BsConst_BsConst_Illumination_ReservedByte_SafeCopy2
          OA_rp_CS_MemAbsSet_Set_BsConst_Compensation_Line_Slope_m: operation=rp_CS_MemAbsSet.Set_BsConst_Compensation_Line_Slope_m
          OA_rp_CS_MemAbsSet_Set_BsConst_Compensation_Line_Shift_b: operation=rp_CS_MemAbsSet.Set_BsConst_Compensation_Line_Shift_b
          OA_rp_CS_MemAbsSet_Set_BsConst_Lookup_Curve_HotSpot_Coef_X: operation=rp_CS_MemAbsSet.Set_BsConst_Lookup_Curve_HotSpot_Coef_X
          OA_rp_CS_MemAbsSet_Set_BsConst_Lookup_Curve_HotSpot_Coef_Y: operation=rp_CS_MemAbsSet.Set_BsConst_Lookup_Curve_HotSpot_Coef_Y
          OA_rp_CS_MemAbsSet_Set_BsConst_Temp_Threshold_Hysteresis_Derating: operation=rp_CS_MemAbsSet.Set_BsConst_Temp_Threshold_Hysteresis_Derating
          OA_rp_CS_MemAbsSet_Set_BsConst_Derating_Backlight_Disable: operation=rp_CS_MemAbsSet.Set_BsConst_Derating_Backlight_Disable
          OA_rp_CS_MemAbsSet_Set_BsConst_Temperature_Sensor_Conv: operation=rp_CS_MemAbsSet.Set_BsConst_Temperature_Sensor_Conv
          OA_rp_CS_MemAbsSet_Set_BsConst_PCB_Temperature_Sensor_Conv: operation=rp_CS_MemAbsSet.Set_BsConst_PCB_Temperature_Sensor_Conv
          OA_rp_CS_MemAbsSet_Set_BsConst_Display_Illum_Max_Level: operation=rp_CS_MemAbsSet.Set_BsConst_Display_Illum_Max_Level
          OA_rp_CS_MemAbsSet_Set_BsConst_PWM_boost_bypass_duty: operation=rp_CS_MemAbsSet.Set_BsConst_PWM_boost_bypass_duty
          OA_rp_CS_MemAbsSet_Set_BsConst_BsConst_Illumination_ReservedByte: operation=rp_CS_MemAbsSet.Set_BsConst_BsConst_Illumination_ReservedByte
          OA_rp_CS_MemAbsSet_Set_BsConst_Compensation_Line_Slope_m_SafeCopy1: operation=rp_CS_MemAbsSet.Set_BsConst_Compensation_Line_Slope_m_SafeCopy1
          OA_rp_CS_MemAbsSet_Set_BsConst_Compensation_Line_Shift_b_SafeCopy1: operation=rp_CS_MemAbsSet.Set_BsConst_Compensation_Line_Shift_b_SafeCopy1
          OA_rp_CS_MemAbsSet_Set_BsConst_Lookup_Curve_HotSpot_Coef_X_SafeCopy1: operation=rp_CS_MemAbsSet.Set_BsConst_Lookup_Curve_HotSpot_Coef_X_SafeCopy1
          OA_rp_CS_MemAbsSet_Set_BsConst_Lookup_Curve_HotSpot_Coef_Y_SafeCopy1: operation=rp_CS_MemAbsSet.Set_BsConst_Lookup_Curve_HotSpot_Coef_Y_SafeCopy1
          OA_rp_CS_MemAbsSet_Set_BsConst_Temp_Threshold_Hysteresis_Derating_SafeCopy1: operation=rp_CS_MemAbsSet.Set_BsConst_Temp_Threshold_Hysteresis_Derating_SafeCopy1
          OA_rp_CS_MemAbsSet_Set_BsConst_Derating_Backlight_Disable_SafeCopy1: operation=rp_CS_MemAbsSet.Set_BsConst_Derating_Backlight_Disable_SafeCopy1
          OA_rp_CS_MemAbsSet_Set_BsConst_Temperature_Sensor_Conv_SafeCopy1: operation=rp_CS_MemAbsSet.Set_BsConst_Temperature_Sensor_Conv_SafeCopy1
          OA_rp_CS_MemAbsSet_Set_BsConst_PCB_Temperature_Sensor_Conv_SafeCopy1: operation=rp_CS_MemAbsSet.Set_BsConst_PCB_Temperature_Sensor_Conv_SafeCopy1
          OA_rp_CS_MemAbsSet_Set_BsConst_Display_Illum_Max_Level_SafeCopy1: operation=rp_CS_MemAbsSet.Set_BsConst_Display_Illum_Max_Level_SafeCopy1
          OA_rp_CS_MemAbsSet_Set_BsConst_PWM_boost_bypass_duty_SafeCopy1: operation=rp_CS_MemAbsSet.Set_BsConst_PWM_boost_bypass_duty_SafeCopy1
          OA_rp_CS_MemAbsSet_Set_BsConst_BsConst_Illumination_ReservedByte_SafeCopy1: operation=rp_CS_MemAbsSet.Set_BsConst_BsConst_Illumination_ReservedByte_SafeCopy1
          OA_rp_CS_MemAbsSet_Set_BsConst_Compensation_Line_Slope_m_SafeCopy2: operation=rp_CS_MemAbsSet.Set_BsConst_Compensation_Line_Slope_m_SafeCopy2
          OA_rp_CS_MemAbsSet_Set_BsConst_Compensation_Line_Shift_b_SafeCopy2: operation=rp_CS_MemAbsSet.Set_BsConst_Compensation_Line_Shift_b_SafeCopy2
          OA_rp_CS_MemAbsSet_Set_BsConst_Lookup_Curve_HotSpot_Coef_X_SafeCopy2: operation=rp_CS_MemAbsSet.Set_BsConst_Lookup_Curve_HotSpot_Coef_X_SafeCopy2
          OA_rp_CS_MemAbsSet_Set_BsConst_Lookup_Curve_HotSpot_Coef_Y_SafeCopy2: operation=rp_CS_MemAbsSet.Set_BsConst_Lookup_Curve_HotSpot_Coef_Y_SafeCopy2
          OA_rp_CS_MemAbsSet_Set_BsConst_Temp_Threshold_Hysteresis_Derating_SafeCopy2: operation=rp_CS_MemAbsSet.Set_BsConst_Temp_Threshold_Hysteresis_Derating_SafeCopy2
          OA_rp_CS_MemAbsSet_Set_BsConst_Derating_Backlight_Disable_SafeCopy2: operation=rp_CS_MemAbsSet.Set_BsConst_Derating_Backlight_Disable_SafeCopy2
          OA_rp_CS_MemAbsSet_Set_BsConst_Temperature_Sensor_Conv_SafeCopy2: operation=rp_CS_MemAbsSet.Set_BsConst_Temperature_Sensor_Conv_SafeCopy2
          OA_rp_CS_MemAbsSet_Set_BsConst_PCB_Temperature_Sensor_Conv_SafeCopy2: operation=rp_CS_MemAbsSet.Set_BsConst_PCB_Temperature_Sensor_Conv_SafeCopy2
          OA_rp_CS_MemAbsSet_Set_BsConst_Display_Illum_Max_Level_SafeCopy2: operation=rp_CS_MemAbsSet.Set_BsConst_Display_Illum_Max_Level_SafeCopy2
          OA_rp_CS_MemAbsSet_Set_BsConst_PWM_boost_bypass_duty_SafeCopy2: operation=rp_CS_MemAbsSet.Set_BsConst_PWM_boost_bypass_duty_SafeCopy2
          OA_rp_CS_MemAbsSet_Set_BsConst_BsConst_Illumination_ReservedByte_SafeCopy2: operation=rp_CS_MemAbsSet.Set_BsConst_BsConst_Illumination_ReservedByte_SafeCopy2
          OA_rp_GetNVM_IlluminationData_Get_BsConst_Compensation_Line_Slope_m: operation=rp_GetNVM_IlluminationData.Get_BsConst_Compensation_Line_Slope_m
          OA_rp_GetNVM_IlluminationData_Get_BsConst_Compensation_Line_Shift_b: operation=rp_GetNVM_IlluminationData.Get_BsConst_Compensation_Line_Shift_b
          OA_rp_GetNVM_IlluminationData_Get_BsConst_Lookup_Curve_HotSpot_Coef_X: operation=rp_GetNVM_IlluminationData.Get_BsConst_Lookup_Curve_HotSpot_Coef_X
          OA_rp_GetNVM_IlluminationData_Get_BsConst_Lookup_Curve_HotSpot_Coef_Y: operation=rp_GetNVM_IlluminationData.Get_BsConst_Lookup_Curve_HotSpot_Coef_Y
          OA_rp_GetNVM_IlluminationData_Get_BsConst_Temp_Threshold_Hysteresis_Derating: operation=rp_GetNVM_IlluminationData.Get_BsConst_Temp_Threshold_Hysteresis_Derating
          OA_rp_GetNVM_IlluminationData_Get_BsConst_Derating_Backlight_Disable: operation=rp_GetNVM_IlluminationData.Get_BsConst_Derating_Backlight_Disable
          OA_rp_GetNVM_IlluminationData_Get_BsConst_Temperature_Sensor_Conv: operation=rp_GetNVM_IlluminationData.Get_BsConst_Temperature_Sensor_Conv
          OA_rp_GetNVM_IlluminationData_Get_BsConst_PCB_Temperature_Sensor_Conv: operation=rp_GetNVM_IlluminationData.Get_BsConst_PCB_Temperature_Sensor_Conv
          OA_rp_GetNVM_IlluminationData_Get_BsConst_Display_Illum_Max_Level: operation=rp_GetNVM_IlluminationData.Get_BsConst_Display_Illum_Max_Level
          OA_rp_GetNVM_IlluminationData_Get_BsConst_PWM_boost_bypass_duty: operation=rp_GetNVM_IlluminationData.Get_BsConst_PWM_boost_bypass_duty
          OA_rp_GetNVM_IlluminationData_Get_BsConst_BsConst_Illumination_ReservedByte: operation=rp_GetNVM_IlluminationData.Get_BsConst_BsConst_Illumination_ReservedByte
          OA_rp_GetNVM_IlluminationData_Get_BsConst_Compensation_Line_Slope_m_SafeCopy1: operation=rp_GetNVM_IlluminationData.Get_BsConst_Compensation_Line_Slope_m_SafeCopy1
          OA_rp_GetNVM_IlluminationData_Get_BsConst_Compensation_Line_Shift_b_SafeCopy1: operation=rp_GetNVM_IlluminationData.Get_BsConst_Compensation_Line_Shift_b_SafeCopy1
          OA_rp_GetNVM_IlluminationData_Get_BsConst_Lookup_Curve_HotSpot_Coef_X_SafeCopy1: operation=rp_GetNVM_IlluminationData.Get_BsConst_Lookup_Curve_HotSpot_Coef_X_SafeCopy1
          OA_rp_GetNVM_IlluminationData_Get_BsConst_Lookup_Curve_HotSpot_Coef_Y_SafeCopy1: operation=rp_GetNVM_IlluminationData.Get_BsConst_Lookup_Curve_HotSpot_Coef_Y_SafeCopy1
          OA_rp_GetNVM_IlluminationData_Get_BsConst_Temp_Threshold_Hysteresis_Derating_SafeCopy1: operation=rp_GetNVM_IlluminationData.Get_BsConst_Temp_Threshold_Hysteresis_Derating_SafeCopy1
          OA_rp_GetNVM_IlluminationData_Get_BsConst_Derating_Backlight_Disable_SafeCopy1: operation=rp_GetNVM_IlluminationData.Get_BsConst_Derating_Backlight_Disable_SafeCopy1
          OA_rp_GetNVM_IlluminationData_Get_BsConst_Temperature_Sensor_Conv_SafeCopy1: operation=rp_GetNVM_IlluminationData.Get_BsConst_Temperature_Sensor_Conv_SafeCopy1
          OA_rp_GetNVM_IlluminationData_Get_BsConst_PCB_Temperature_Sensor_Conv_SafeCopy1: operation=rp_GetNVM_IlluminationData.Get_BsConst_PCB_Temperature_Sensor_Conv_SafeCopy1
          OA_rp_GetNVM_IlluminationData_Get_BsConst_Display_Illum_Max_Level_SafeCopy1: operation=rp_GetNVM_IlluminationData.Get_BsConst_Display_Illum_Max_Level_SafeCopy1
          OA_rp_GetNVM_IlluminationData_Get_BsConst_PWM_boost_bypass_duty_SafeCopy1: operation=rp_GetNVM_IlluminationData.Get_BsConst_PWM_boost_bypass_duty_SafeCopy1
          OA_rp_GetNVM_IlluminationData_Get_BsConst_BsConst_Illumination_ReservedByte_SafeCopy1: operation=rp_GetNVM_IlluminationData.Get_BsConst_BsConst_Illumination_ReservedByte_SafeCopy1
          OA_rp_GetNVM_IlluminationData_Get_BsConst_Compensation_Line_Slope_m_SafeCopy2: operation=rp_GetNVM_IlluminationData.Get_BsConst_Compensation_Line_Slope_m_SafeCopy2
          OA_rp_GetNVM_IlluminationData_Get_BsConst_Compensation_Line_Shift_b_SafeCopy2: operation=rp_GetNVM_IlluminationData.Get_BsConst_Compensation_Line_Shift_b_SafeCopy2
          OA_rp_GetNVM_IlluminationData_Get_BsConst_Lookup_Curve_HotSpot_Coef_X_SafeCopy2: operation=rp_GetNVM_IlluminationData.Get_BsConst_Lookup_Curve_HotSpot_Coef_X_SafeCopy2
          OA_rp_GetNVM_IlluminationData_Get_BsConst_Lookup_Curve_HotSpot_Coef_Y_SafeCopy2: operation=rp_GetNVM_IlluminationData.Get_BsConst_Lookup_Curve_HotSpot_Coef_Y_SafeCopy2
          OA_rp_GetNVM_IlluminationData_Get_BsConst_Temp_Threshold_Hysteresis_Derating_SafeCopy2: operation=rp_GetNVM_IlluminationData.Get_BsConst_Temp_Threshold_Hysteresis_Derating_SafeCopy2
          OA_rp_GetNVM_IlluminationData_Get_BsConst_Derating_Backlight_Disable_SafeCopy2: operation=rp_GetNVM_IlluminationData.Get_BsConst_Derating_Backlight_Disable_SafeCopy2
          OA_rp_GetNVM_IlluminationData_Get_BsConst_Temperature_Sensor_Conv_SafeCopy2: operation=rp_GetNVM_IlluminationData.Get_BsConst_Temperature_Sensor_Conv_SafeCopy2
          OA_rp_GetNVM_IlluminationData_Get_BsConst_PCB_Temperature_Sensor_Conv_SafeCopy2: operation=rp_GetNVM_IlluminationData.Get_BsConst_PCB_Temperature_Sensor_Conv_SafeCopy2
          OA_rp_GetNVM_IlluminationData_Get_BsConst_Display_Illum_Max_Level_SafeCopy2: operation=rp_GetNVM_IlluminationData.Get_BsConst_Display_Illum_Max_Level_SafeCopy2
          OA_rp_GetNVM_IlluminationData_Get_BsConst_PWM_boost_bypass_duty_SafeCopy2: operation=rp_GetNVM_IlluminationData.Get_BsConst_PWM_boost_bypass_duty_SafeCopy2
          OA_rp_GetNVM_IlluminationData_Get_BsConst_BsConst_Illumination_ReservedByte_SafeCopy2: operation=rp_GetNVM_IlluminationData.Get_BsConst_BsConst_Illumination_ReservedByte_SafeCopy2
          OA_rp_SetNVM_IlluminationData_Set_BsConst_Compensation_Line_Slope_m: operation=rp_SetNVM_IlluminationData.Set_BsConst_Compensation_Line_Slope_m
          OA_rp_SetNVM_IlluminationData_Set_BsConst_Compensation_Line_Shift_b: operation=rp_SetNVM_IlluminationData.Set_BsConst_Compensation_Line_Shift_b
          OA_rp_SetNVM_IlluminationData_Set_BsConst_Lookup_Curve_HotSpot_Coef_X: operation=rp_SetNVM_IlluminationData.Set_BsConst_Lookup_Curve_HotSpot_Coef_X
          OA_rp_SetNVM_IlluminationData_Set_BsConst_Lookup_Curve_HotSpot_Coef_Y: operation=rp_SetNVM_IlluminationData.Set_BsConst_Lookup_Curve_HotSpot_Coef_Y
          OA_rp_SetNVM_IlluminationData_Set_BsConst_Temp_Threshold_Hysteresis_Derating: operation=rp_SetNVM_IlluminationData.Set_BsConst_Temp_Threshold_Hysteresis_Derating
          OA_rp_SetNVM_IlluminationData_Set_BsConst_Derating_Backlight_Disable: operation=rp_SetNVM_IlluminationData.Set_BsConst_Derating_Backlight_Disable
          OA_rp_SetNVM_IlluminationData_Set_BsConst_Temperature_Sensor_Conv: operation=rp_SetNVM_IlluminationData.Set_BsConst_Temperature_Sensor_Conv
          OA_rp_SetNVM_IlluminationData_Set_BsConst_PCB_Temperature_Sensor_Conv: operation=rp_SetNVM_IlluminationData.Set_BsConst_PCB_Temperature_Sensor_Conv
          OA_rp_SetNVM_IlluminationData_Set_BsConst_Display_Illum_Max_Level: operation=rp_SetNVM_IlluminationData.Set_BsConst_Display_Illum_Max_Level
          OA_rp_SetNVM_IlluminationData_Set_BsConst_PWM_boost_bypass_duty: operation=rp_SetNVM_IlluminationData.Set_BsConst_PWM_boost_bypass_duty
          OA_rp_SetNVM_IlluminationData_Set_BsConst_BsConst_Illumination_ReservedByte: operation=rp_SetNVM_IlluminationData.Set_BsConst_BsConst_Illumination_ReservedByte
          OA_rp_SetNVM_IlluminationData_Set_BsConst_Compensation_Line_Slope_m_SafeCopy1: operation=rp_SetNVM_IlluminationData.Set_BsConst_Compensation_Line_Slope_m_SafeCopy1
          OA_rp_SetNVM_IlluminationData_Set_BsConst_Compensation_Line_Shift_b_SafeCopy1: operation=rp_SetNVM_IlluminationData.Set_BsConst_Compensation_Line_Shift_b_SafeCopy1
          OA_rp_SetNVM_IlluminationData_Set_BsConst_Lookup_Curve_HotSpot_Coef_X_SafeCopy1: operation=rp_SetNVM_IlluminationData.Set_BsConst_Lookup_Curve_HotSpot_Coef_X_SafeCopy1
          OA_rp_SetNVM_IlluminationData_Set_BsConst_Lookup_Curve_HotSpot_Coef_Y_SafeCopy1: operation=rp_SetNVM_IlluminationData.Set_BsConst_Lookup_Curve_HotSpot_Coef_Y_SafeCopy1
          OA_rp_SetNVM_IlluminationData_Set_BsConst_Temp_Threshold_Hysteresis_Derating_SafeCopy1: operation=rp_SetNVM_IlluminationData.Set_BsConst_Temp_Threshold_Hysteresis_Derating_SafeCopy1
          OA_rp_SetNVM_IlluminationData_Set_BsConst_Derating_Backlight_Disable_SafeCopy1: operation=rp_SetNVM_IlluminationData.Set_BsConst_Derating_Backlight_Disable_SafeCopy1
          OA_rp_SetNVM_IlluminationData_Set_BsConst_Temperature_Sensor_Conv_SafeCopy1: operation=rp_SetNVM_IlluminationData.Set_BsConst_Temperature_Sensor_Conv_SafeCopy1
          OA_rp_SetNVM_IlluminationData_Set_BsConst_PCB_Temperature_Sensor_Conv_SafeCopy1: operation=rp_SetNVM_IlluminationData.Set_BsConst_PCB_Temperature_Sensor_Conv_SafeCopy1
          OA_rp_SetNVM_IlluminationData_Set_BsConst_Display_Illum_Max_Level_SafeCopy1: operation=rp_SetNVM_IlluminationData.Set_BsConst_Display_Illum_Max_Level_SafeCopy1
          OA_rp_SetNVM_IlluminationData_Set_BsConst_PWM_boost_bypass_duty_SafeCopy1: operation=rp_SetNVM_IlluminationData.Set_BsConst_PWM_boost_bypass_duty_SafeCopy1
          OA_rp_SetNVM_IlluminationData_Set_BsConst_BsConst_Illumination_ReservedByte_SafeCopy1: operation=rp_SetNVM_IlluminationData.Set_BsConst_BsConst_Illumination_ReservedByte_SafeCopy1
          OA_rp_SetNVM_IlluminationData_Set_BsConst_Compensation_Line_Slope_m_SafeCopy2: operation=rp_SetNVM_IlluminationData.Set_BsConst_Compensation_Line_Slope_m_SafeCopy2
          OA_rp_SetNVM_IlluminationData_Set_BsConst_Compensation_Line_Shift_b_SafeCopy2: operation=rp_SetNVM_IlluminationData.Set_BsConst_Compensation_Line_Shift_b_SafeCopy2
          OA_rp_SetNVM_IlluminationData_Set_BsConst_Lookup_Curve_HotSpot_Coef_X_SafeCopy2: operation=rp_SetNVM_IlluminationData.Set_BsConst_Lookup_Curve_HotSpot_Coef_X_SafeCopy2
          OA_rp_SetNVM_IlluminationData_Set_BsConst_Lookup_Curve_HotSpot_Coef_Y_SafeCopy2: operation=rp_SetNVM_IlluminationData.Set_BsConst_Lookup_Curve_HotSpot_Coef_Y_SafeCopy2
          OA_rp_SetNVM_IlluminationData_Set_BsConst_Temp_Threshold_Hysteresis_Derating_SafeCopy2: operation=rp_SetNVM_IlluminationData.Set_BsConst_Temp_Threshold_Hysteresis_Derating_SafeCopy2
          OA_rp_SetNVM_IlluminationData_Set_BsConst_Derating_Backlight_Disable_SafeCopy2: operation=rp_SetNVM_IlluminationData.Set_BsConst_Derating_Backlight_Disable_SafeCopy2
          OA_rp_SetNVM_IlluminationData_Set_BsConst_Temperature_Sensor_Conv_SafeCopy2: operation=rp_SetNVM_IlluminationData.Set_BsConst_Temperature_Sensor_Conv_SafeCopy2
          OA_rp_SetNVM_IlluminationData_Set_BsConst_PCB_Temperature_Sensor_Conv_SafeCopy2: operation=rp_SetNVM_IlluminationData.Set_BsConst_PCB_Temperature_Sensor_Conv_SafeCopy2
          OA_rp_SetNVM_IlluminationData_Set_BsConst_Display_Illum_Max_Level_SafeCopy2: operation=rp_SetNVM_IlluminationData.Set_BsConst_Display_Illum_Max_Level_SafeCopy2
          OA_rp_SetNVM_IlluminationData_Set_BsConst_PWM_boost_bypass_duty_SafeCopy2: operation=rp_SetNVM_IlluminationData.Set_BsConst_PWM_boost_bypass_duty_SafeCopy2
          OA_rp_SetNVM_IlluminationData_Set_BsConst_BsConst_Illumination_ReservedByte_SafeCopy2: operation=rp_SetNVM_IlluminationData.Set_BsConst_BsConst_Illumination_ReservedByte_SafeCopy2
  swc implementation IMPL_Mdl_Dim: behavior=IB_Mdl_Dim
